VERSION ""

NS_ :

BS_:

BU_: SEAT HEADLAMP CLUSTER EMS ABS IMU KEYLESS_ECU ISG TESTER

BO_ 3221225472 VECTOR__INDEPENDENT_SIG_MSG: 0 Vector__XXX
 SG_ CC_TORQUE_REQ_STATUS_ENG_FB_Copy : 0|2@1+ (1,0) [0|2] " " Vector__XXX
 SG_ DNP_IMMOBILIZER_LAMP_INDICATION : 0|1@1+ (1,0) [0|1] "nan" Vector__XXX
 SG_ DNP_HEADLAMP_STATUS : 0|1@1+ (1,0) [0|1] "nan" Vector__XXX
 SG_ HEATED_GRIP_FEAT_EN : 0|1@1+ (1,0) [0|1] "nan" Vector__XXX
 SG_ HAPTIC_GRIP_FEAT_EN : 0|1@1+ (1,0) [0|1] "nan" Vector__XXX
 SG_ WINDSHIELD_FEAT_EN : 0|1@1+ (1,0) [0|1] "nan" Vector__XXX
 SG_ KEYLESS_FEAT_EN : 0|1@1+ (1,0) [0|1] "nan" Vector__XXX
 SG_ CLIMATIC_SEAT_FEAT_EN : 0|1@1+ (1,0) [0|1] "nan" Vector__XXX
 SG_ HOT_SEAT_FEAT_EN : 0|1@1+ (1,0) [0|1] "nan" Vector__XXX
 SG_ FEATURE_EN_LC : 0|1@1+ (1,0) [0|1] " " Vector__XXX

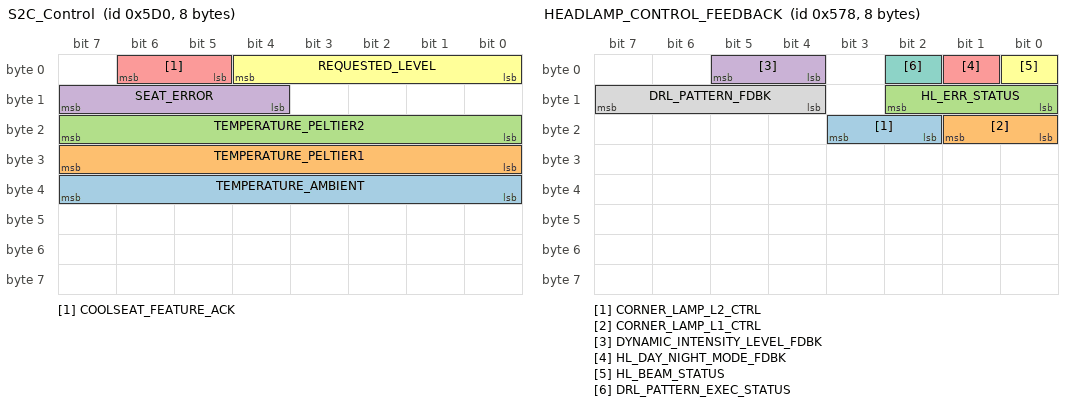
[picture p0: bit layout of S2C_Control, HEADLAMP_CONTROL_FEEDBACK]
BO_ 1488 S2C_Control: 8 SEAT
 SG_ TEMPERATURE_AMBIENT : 32|8@1+ (1,-20) [-20|235] "degC" Vector__XXX
 SG_ TEMPERATURE_PELTIER1 : 24|8@1+ (1,-20) [-20|235] "degC" Vector__XXX
 SG_ TEMPERATURE_PELTIER2 : 16|8@1+ (1,-20) [-20|235] "degC" Vector__XXX
 SG_ SEAT_ERROR : 12|4@1+ (1,0) [0|15] "nan" Vector__XXX
 SG_ COOLSEAT_FEATURE_ACK : 5|2@1+ (1,0) [0|3] "nan" Vector__XXX
 SG_ REQUESTED_LEVEL : 0|5@1+ (1,0) [0|31] " " Vector__XXX

BO_ 1489 C2S_Control: 8 Vector__XXX
 SG_ COOLSEAT_FEATURE_EN : 5|2@1+ (1,0) [0|3] "nan"  SEAT
 SG_ TARGET_LEVEL : 0|5@1+ (1,0) [0|31] " "  SEAT

BO_ 852 PecuOutputMsg2: 8 Vector__XXX
 SG_ KEYFOB_LOWBATTERY_WARN : 1|1@1+ (1,0) [0|1] "nan" Vector__XXX
 SG_ NO_KEYFOB_DETECTED_WARN : 0|1@1+ (1,0) [0|1] "nan" Vector__XXX

BO_ 1400 HEADLAMP_CONTROL_FEEDBACK: 8 Vector__XXX
 SG_ CORNER_LAMP_L2_CTRL : 18|2@1+ (1,0) [0|3] "nan"  CLUSTER
 SG_ CORNER_LAMP_L1_CTRL : 16|2@1+ (1,0) [0|3] "nan"  CLUSTER
 SG_ HL_ERR_STATUS : 8|3@1+ (1,0) [0|7] "nan"  CLUSTER
 SG_ DYNAMIC_INTENSITY_LEVEL_FDBK : 4|2@1+ (1,0) [0|3] "nan"  CLUSTER
 SG_ HL_DAY_NIGHT_MODE_FDBK : 1|1@1+ (1,0) [0|1] "nan"  CLUSTER
 SG_ HL_BEAM_STATUS : 0|1@1+ (1,0) [0|1] "nan"  CLUSTER
 SG_ DRL_PATTERN_EXEC_STATUS : 2|1@1+ (1,0) [0|1] "nan"  CLUSTER
 SG_ DRL_PATTERN_FDBK : 12|4@1+ (1,0) [0|15] "nan"  CLUSTER

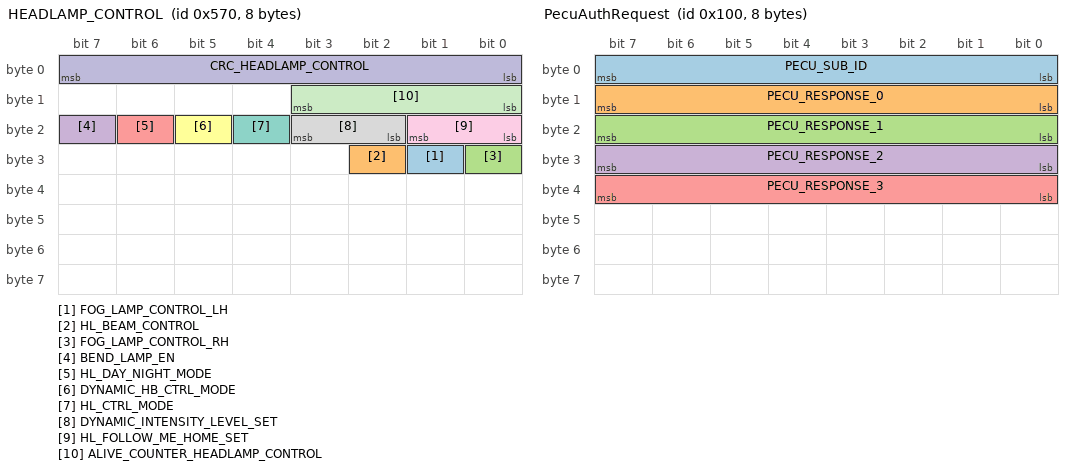
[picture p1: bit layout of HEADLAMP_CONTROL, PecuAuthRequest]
BO_ 1392 HEADLAMP_CONTROL: 8 CLUSTER
 SG_ FOG_LAMP_CONTROL_LH : 25|1@1+ (1,0) [0|1] "nan" Vector__XXX
 SG_ HL_BEAM_CONTROL : 26|1@1+ (1,0) [0|1] "nan"  HEADLAMP
 SG_ FOG_LAMP_CONTROL_RH : 24|1@1+ (1,0) [0|1] "nan" Vector__XXX
 SG_ BEND_LAMP_EN : 23|1@1+ (1,0) [0|1] "nan"  HEADLAMP
 SG_ HL_DAY_NIGHT_MODE : 22|1@1+ (1,0) [0|1] "nan"  HEADLAMP
 SG_ DYNAMIC_HB_CTRL_MODE : 21|1@1+ (1,0) [0|1] "nan"  HEADLAMP
 SG_ HL_CTRL_MODE : 20|1@1+ (1,0) [0|1] "nan"  HEADLAMP
 SG_ DYNAMIC_INTENSITY_LEVEL_SET : 18|2@1+ (1,0) [0|3] "nan"  HEADLAMP
 SG_ HL_FOLLOW_ME_HOME_SET : 16|2@1+ (1,0) [0|3] "nan"  HEADLAMP
 SG_ CRC_HEADLAMP_CONTROL : 0|8@1+ (1,0) [0|255] "nan"  HEADLAMP
 SG_ ALIVE_COUNTER_HEADLAMP_CONTROL : 8|4@1+ (1,0) [0|14] "nan"  HEADLAMP

BO_ 2017 TESTER_REQUEST_HECU_ABS: 8 TESTER
 SG_ TESTER_REQUEST_HECU_ABS : 0|64@1+ (1,0) [0|1] "nan" Vector__XXX

BO_ 2025 ABS_HECU_DIAG_RESPONSE: 8 ABS
 SG_ ABS_HECU_DIAG_RESPONSE : 0|64@1+ (1,0) [0|1] "nan"  TESTER

BO_ 2024 EMS_DIAG_RESPONSE: 8 EMS
 SG_ ABS_HECU_DIAG_RESPONSE : 0|64@1+ (1,0) [0|1] "nan" Vector__XXX

BO_ 256 PecuAuthRequest: 8 KEYLESS_ECU
 SG_ PECU_SUB_ID : 0|8@1+ (1,0) [0|255] "nan"  EMS
 SG_ PECU_RESPONSE_0 : 8|8@1+ (1,0) [0|255] "nan"  EMS
 SG_ PECU_RESPONSE_1 : 16|8@1+ (1,0) [0|255] "nan"  EMS
 SG_ PECU_RESPONSE_2 : 24|8@1+ (1,0) [0|255] "nan"  EMS
 SG_ PECU_RESPONSE_3 : 32|8@1+ (1,0) [0|255] "nan"  EMS

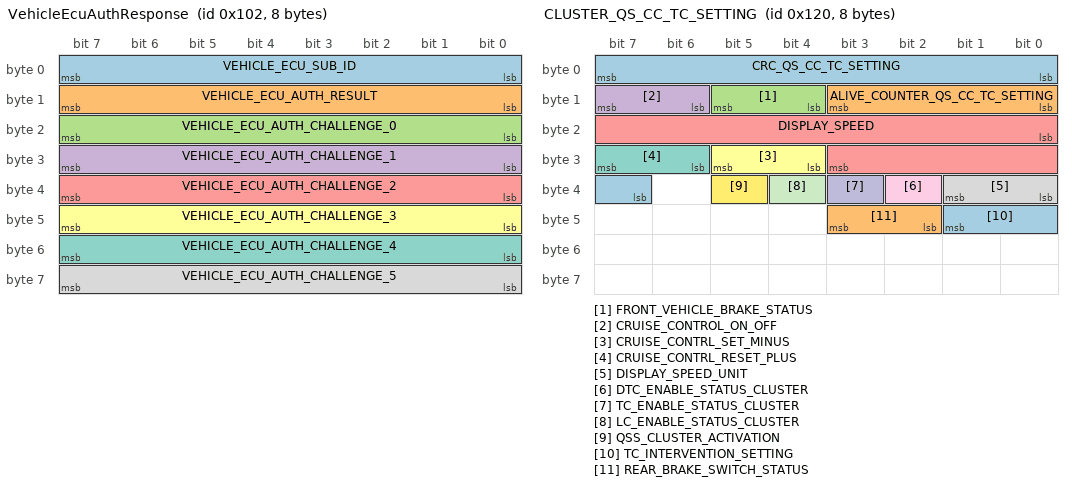
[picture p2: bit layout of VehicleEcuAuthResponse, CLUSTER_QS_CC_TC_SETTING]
BO_ 258 VehicleEcuAuthResponse: 8 EMS
 SG_ VEHICLE_ECU_SUB_ID : 0|8@1+ (1,0) [0|255] "nan"  KEYLESS_ECU
 SG_ VEHICLE_ECU_AUTH_RESULT : 8|8@1+ (1,0) [0|255] "nan"  KEYLESS_ECU
 SG_ VEHICLE_ECU_AUTH_CHALLENGE_0 : 16|8@1+ (1,0) [0|255] "nan"  KEYLESS_ECU
 SG_ VEHICLE_ECU_AUTH_CHALLENGE_1 : 24|8@1+ (1,0) [0|255] "nan"  KEYLESS_ECU
 SG_ VEHICLE_ECU_AUTH_CHALLENGE_2 : 32|8@1+ (1,0) [0|255] "nan"  KEYLESS_ECU
 SG_ VEHICLE_ECU_AUTH_CHALLENGE_3 : 40|8@1+ (1,0) [0|255] "nan"  KEYLESS_ECU
 SG_ VEHICLE_ECU_AUTH_CHALLENGE_4 : 48|8@1+ (1,0) [0|255] "nan"  KEYLESS_ECU
 SG_ VEHICLE_ECU_AUTH_CHALLENGE_5 : 56|8@1+ (1,0) [0|255] "nan"  KEYLESS_ECU

BO_ 288 CLUSTER_QS_CC_TC_SETTING: 8 CLUSTER
 SG_ CRC_QS_CC_TC_SETTING : 0|8@1+ (1,0) [0|255] "nan"  ABS,EMS
 SG_ ALIVE_COUNTER_QS_CC_TC_SETTING : 8|4@1+ (1,0) [0|14] "nan"  ABS,EMS
 SG_ FRONT_VEHICLE_BRAKE_STATUS : 12|2@1+ (1,0) [0|2] "nan"  ABS,EMS
 SG_ CRUISE_CONTROL_ON_OFF : 14|2@1+ (1,0) [0|2] "nan"  ABS,EMS
 SG_ DISPLAY_SPEED : 16|12@1+ (0.1,0) [0|409.4] "km/h"  ABS,EMS
 SG_ CRUISE_CONTRL_SET_MINUS : 28|2@1+ (1,0) [0|2] "nan"  ABS,EMS
 SG_ CRUISE_CONTRL_RESET_PLUS : 30|2@1+ (1,0) [0|2] "nan"  ABS,EMS
 SG_ DISPLAY_SPEED_UNIT : 32|2@1+ (1,0) [0|2] "nan"  ABS,EMS
 SG_ DTC_ENABLE_STATUS_CLUSTER : 34|1@1+ (1,0) [0|1] "nan"  ABS,EMS
 SG_ TC_ENABLE_STATUS_CLUSTER : 35|1@1+ (1,0) [0|1] "nan"  ABS,EMS
 SG_ LC_ENABLE_STATUS_CLUSTER : 36|1@1+ (1,0) [0|1] "nan"  ABS,EMS
 SG_ QSS_CLUSTER_ACTIVATION : 37|1@1+ (1,0) [0|1] "nan"  ABS,EMS
 SG_ TC_INTERVENTION_SETTING : 39|3@1+ (1,0) [0|6] "nan"  ABS,EMS
 SG_ REAR_BRAKE_SWITCH_STATUS : 42|2@1+ (1,0) [0|2] "nan"  ABS,EMS

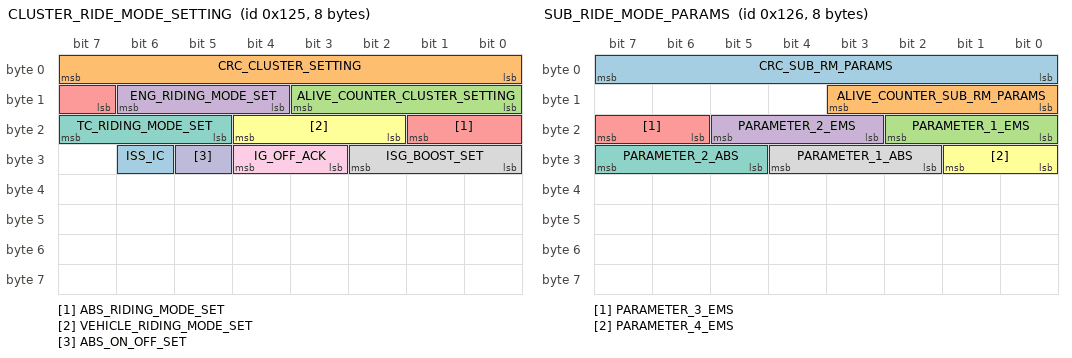
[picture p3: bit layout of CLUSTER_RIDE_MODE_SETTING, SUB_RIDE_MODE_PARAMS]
BO_ 293 CLUSTER_RIDE_MODE_SETTING: 8 CLUSTER
 SG_ ISS_IC : 30|1@1+ (1,0) [0|1] "nan"  EMS
 SG_ CRC_CLUSTER_SETTING : 0|8@1+ (1,0) [0|255] "nan"  EMS,ABS,ISG
 SG_ ALIVE_COUNTER_CLUSTER_SETTING : 8|4@1+ (1,0) [0|14] "nan"  EMS,ABS,ISG
 SG_ ENG_RIDING_MODE_SET : 12|3@1+ (1,0) [0|6] "nan"  EMS,ABS,ISG
 SG_ ABS_RIDING_MODE_SET : 15|3@1+ (1,0) [0|6] "nan"  EMS,ABS,ISG
 SG_ VEHICLE_RIDING_MODE_SET : 18|3@1+ (1,0) [0|6] "nan"  EMS,ABS,ISG
 SG_ TC_RIDING_MODE_SET : 21|3@1+ (1,0) [0|6] "nan"  EMS,ABS,ISG
 SG_ ISG_BOOST_SET : 24|3@1+ (1,0) [0|6] "nan"  EMS,ABS,ISG
 SG_ IG_OFF_ACK : 27|2@1+ (1,0) [0|2] "nan"  EMS,ABS,ISG
 SG_ ABS_ON_OFF_SET : 29|1@1+ (1,0) [0|1] "nan"  EMS,ABS,ISG

BO_ 294 SUB_RIDE_MODE_PARAMS: 8 CLUSTER
 SG_ CRC_SUB_RM_PARAMS : 0|8@1+ (1,0) [0|255] "nan"  EMS,ABS,ISG
 SG_ ALIVE_COUNTER_SUB_RM_PARAMS : 8|4@1+ (1,0) [0|14] "nan"  EMS,ABS,ISG
 SG_ PARAMETER_1_EMS : 16|3@1+ (1,0) [0|7] "nan"  EMS,ISG
 SG_ PARAMETER_2_EMS : 19|3@1+ (1,0) [0|7] "nan"  EMS,ISG
 SG_ PARAMETER_3_EMS : 22|2@1+ (1,0) [0|3] "nan"  EMS,ISG
 SG_ PARAMETER_4_EMS : 24|2@1+ (1,0) [0|3] "nan"  EMS,ISG
 SG_ PARAMETER_2_ABS : 29|3@1+ (1,0) [0|7] "nan"  ABS,ISG
 SG_ PARAMETER_1_ABS : 26|3@1+ (1,0) [0|7] "nan"  ABS,ISG

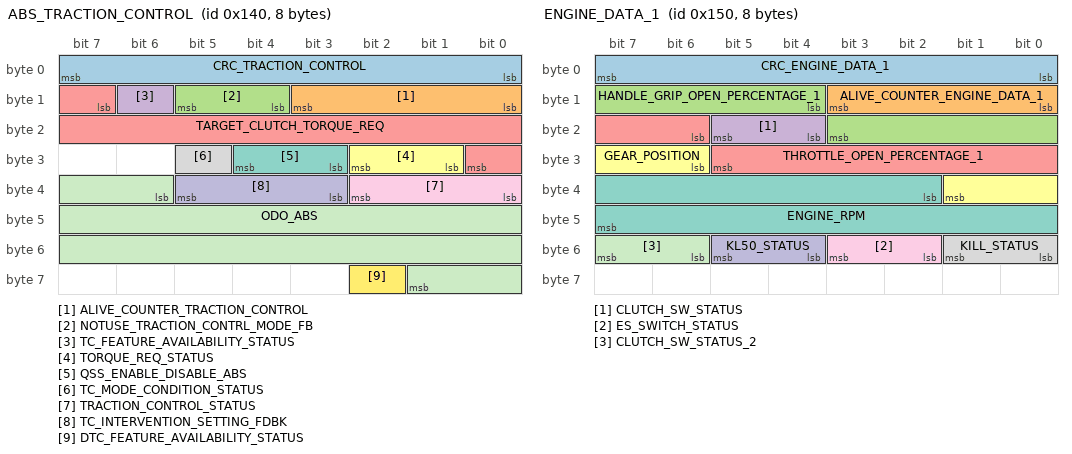
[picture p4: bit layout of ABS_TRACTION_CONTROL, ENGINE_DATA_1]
BO_ 320 ABS_TRACTION_CONTROL: 8 ABS
 SG_ CRC_TRACTION_CONTROL : 0|8@1+ (1,0) [0|255] "nan"  CLUSTER,EMS
 SG_ ALIVE_COUNTER_TRACTION_CONTROL : 8|4@1+ (1,0) [0|14] "nan"  CLUSTER,EMS
 SG_ NOTUSE_TRACTION_CONTRL_MODE_FB : 12|2@1+ (1,0) [0|2] "nan"  CLUSTER,EMS
 SG_ TC_FEATURE_AVAILABILITY_STATUS : 14|1@1+ (1,0) [0|1] "nan"  CLUSTER,EMS
 SG_ TARGET_CLUTCH_TORQUE_REQ : 15|10@1+ (0.1,-10) [-10|92.2] "Nm"  CLUSTER,EMS
 SG_ TORQUE_REQ_STATUS : 25|2@1+ (1,0) [0|2] "nan"  CLUSTER,EMS
 SG_ QSS_ENABLE_DISABLE_ABS : 27|2@1+ (1,0) [0|2] "nan"  CLUSTER,EMS
 SG_ TC_MODE_CONDITION_STATUS : 29|1@1+ (1,0) [0|1] "nan"  CLUSTER,EMS
 SG_ TRACTION_CONTROL_STATUS : 32|3@1+ (1,0) [0|6] "nan"  CLUSTER,EMS
 SG_ TC_INTERVENTION_SETTING_FDBK : 35|3@1+ (1,0) [0|6] "nan"  CLUSTER,EMS
 SG_ ODO_ABS : 38|20@1+ (1,0) [0|1048574] "km"  CLUSTER,EMS
 SG_ DTC_FEATURE_AVAILABILITY_STATUS : 58|1@1+ (1,0) [0|1] "nan"  CLUSTER,EMS

BO_ 336 ENGINE_DATA_1: 8 EMS
 SG_ CRC_ENGINE_DATA_1 : 0|8@1+ (1,0) [0|255] "nan"  ABS,CLUSTER,ISG
 SG_ ALIVE_COUNTER_ENGINE_DATA_1 : 8|4@1+ (1,0) [0|14] "nan"  ABS,CLUSTER,ISG
 SG_ HANDLE_GRIP_OPEN_PERCENTAGE_1 : 12|8@1+ (0.5,-20) [-20|107] "%"  ABS,CLUSTER,ISG
 SG_ CLUTCH_SW_STATUS : 20|2@1+ (1,0) [0|3] "nan"  ABS,CLUSTER,ISG
 SG_ THROTTLE_OPEN_PERCENTAGE_1 : 22|8@1+ (0.3937,0) [0|100] "%"  ABS,CLUSTER,ISG
 SG_ GEAR_POSITION : 30|4@1+ (1,0) [0|15] "nan"  ABS,CLUSTER,ISG
 SG_ ENGINE_RPM : 34|14@1+ (1,0) [0|16382] "1/min"  ABS,CLUSTER,ISG
 SG_ KILL_STATUS : 48|2@1+ (1,0) [0|2] "nan"  ABS,CLUSTER,ISG
 SG_ ES_SWITCH_STATUS : 50|2@1+ (1,0) [0|2] "nan"  ABS,CLUSTER,ISG
 SG_ KL50_STATUS : 52|2@1+ (1,0) [0|2] "nan"  ABS,CLUSTER,ISG
 SG_ CLUTCH_SW_STATUS_2 : 54|2@1+ (1,0) [0|3] "nan"  ABS,CLUSTER,ISG

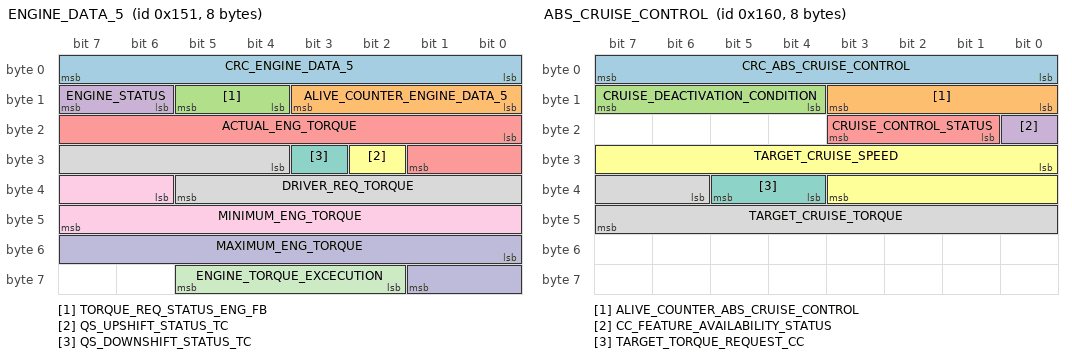
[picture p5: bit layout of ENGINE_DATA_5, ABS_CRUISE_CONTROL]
BO_ 337 ENGINE_DATA_5: 8 EMS
 SG_ CRC_ENGINE_DATA_5 : 0|8@1+ (1,0) [0|255] " "  ABS,CLUSTER
 SG_ ALIVE_COUNTER_ENGINE_DATA_5 : 8|4@1+ (1,0) [0|14] " "  ABS,CLUSTER
 SG_ TORQUE_REQ_STATUS_ENG_FB : 12|2@1+ (1,0) [0|2] " "  ABS,CLUSTER
 SG_ ENGINE_STATUS : 14|2@1+ (1,0) [0|2] " "  ABS,CLUSTER
 SG_ ACTUAL_ENG_TORQUE : 16|10@1+ (0.1,-10) [-10|92.2] "Nm"  ABS,CLUSTER
 SG_ QS_UPSHIFT_STATUS_TC : 26|1@1+ (1,0) [0|1] " "  ABS,CLUSTER
 SG_ QS_DOWNSHIFT_STATUS_TC : 27|1@1+ (1,0) [0|1] " "  ABS,CLUSTER
 SG_ DRIVER_REQ_TORQUE : 28|10@1+ (0.1,-10) [-10|92.2] "Nm"  ABS,CLUSTER
 SG_ MINIMUM_ENG_TORQUE : 38|10@1+ (0.1,-10) [-10|92.2] "Nm"  ABS,CLUSTER
 SG_ MAXIMUM_ENG_TORQUE : 48|10@1+ (0.1,-10) [-10|92.2] "Nm"  ABS,CLUSTER
 SG_ ENGINE_TORQUE_EXCECUTION : 58|4@1+ (1,0) [0|14] " "  ABS,CLUSTER

BO_ 352 ABS_CRUISE_CONTROL: 8 ABS
 SG_ CRC_ABS_CRUISE_CONTROL : 0|8@1+ (1,0) [0|255] "nan"  CLUSTER,EMS
 SG_ ALIVE_COUNTER_ABS_CRUISE_CONTROL : 8|4@1+ (1,0) [0|14] "nan"  CLUSTER,EMS
 SG_ CRUISE_DEACTIVATION_CONDITION : 12|4@1+ (1,0) [0|14] "nan"  CLUSTER,EMS
 SG_ CC_FEATURE_AVAILABILITY_STATUS : 16|1@1+ (1,0) [0|1] "nan"  CLUSTER,EMS
 SG_ CRUISE_CONTROL_STATUS : 17|3@1+ (1,0) [0|6] "nan"  CLUSTER,EMS
 SG_ TARGET_CRUISE_SPEED : 24|12@1+ (0.1,0) [0|409.4] "km/h"  CLUSTER,EMS
 SG_ TARGET_TORQUE_REQUEST_CC : 36|2@1+ (1,0) [0|2] "nan"  CLUSTER,EMS
 SG_ TARGET_CRUISE_TORQUE : 38|10@1+ (0.1,-10) [-10|92.2] "Nm"  CLUSTER,EMS

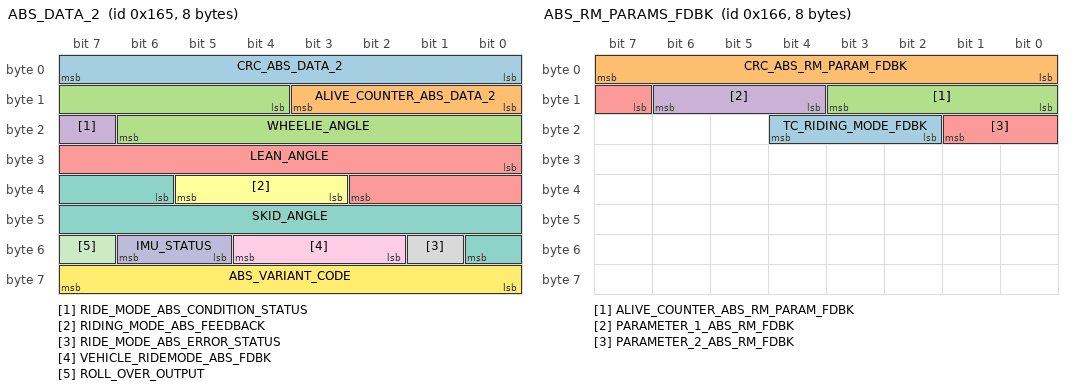
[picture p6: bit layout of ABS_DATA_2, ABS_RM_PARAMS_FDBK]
BO_ 357 ABS_DATA_2: 8 ABS
 SG_ CRC_ABS_DATA_2 : 0|8@1+ (1,0) [0|255] "nan"  EMS,CLUSTER
 SG_ ALIVE_COUNTER_ABS_DATA_2 : 8|4@1+ (1,0) [0|14] "nan"  EMS,CLUSTER
 SG_ WHEELIE_ANGLE : 12|11@1+ (0.1,-90) [-90|90] "deg"  EMS,CLUSTER
 SG_ RIDE_MODE_ABS_CONDITION_STATUS : 23|1@1+ (1,0) [0|1] "nan"  EMS,CLUSTER
 SG_ LEAN_ANGLE : 24|11@1+ (0.1,-90) [-90|90] "deg"  EMS,CLUSTER
 SG_ RIDING_MODE_ABS_FEEDBACK : 35|3@1+ (1,0) [0|6] "nan"  EMS,CLUSTER
 SG_ SKID_ANGLE : 38|11@1+ (0.1,-90) [-90|90] "deg"  EMS,CLUSTER
 SG_ RIDE_MODE_ABS_ERROR_STATUS : 49|1@1+ (1,0) [0|1] "nan"  EMS,CLUSTER
 SG_ VEHICLE_RIDEMODE_ABS_FDBK : 50|3@1+ (1,0) [0|6] "nan"  EMS,CLUSTER
 SG_ IMU_STATUS : 53|2@1+ (1,0) [0|3] "nan"  EMS,CLUSTER
 SG_ ROLL_OVER_OUTPUT : 55|1@1+ (1,0) [0|1] "nan"  EMS,CLUSTER
 SG_ ABS_VARIANT_CODE : 56|8@1+ (1,0) [0|254] "nan"  EMS,CLUSTER

BO_ 358 ABS_RM_PARAMS_FDBK: 8 ABS
 SG_ TC_RIDING_MODE_FDBK : 18|3@1+ (1,0) [0|6] "nan" Vector__XXX
 SG_ CRC_ABS_RM_PARAM_FDBK : 0|8@1+ (1,0) [0|255] "nan"  CLUSTER,EMS
 SG_ ALIVE_COUNTER_ABS_RM_PARAM_FDBK : 8|4@1+ (1,0) [0|14] "nan"  CLUSTER,EMS
 SG_ PARAMETER_1_ABS_RM_FDBK : 12|3@1+ (1,0) [0|7] "nan"  CLUSTER,EMS
 SG_ PARAMETER_2_ABS_RM_FDBK : 15|3@1+ (1,0) [0|7] "nan"  CLUSTER,EMS

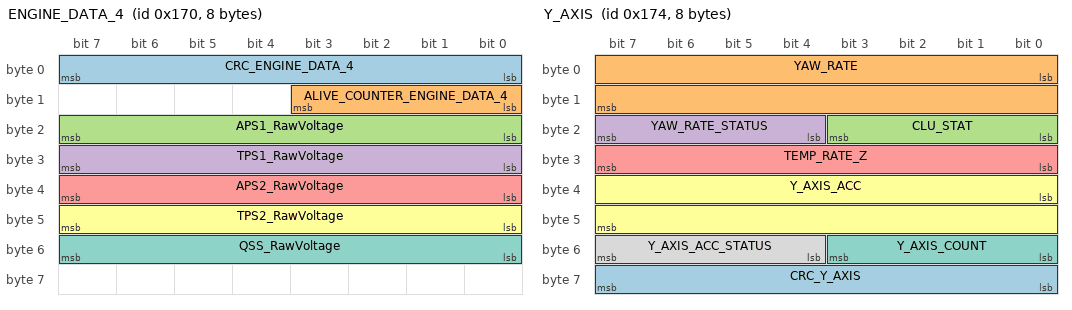
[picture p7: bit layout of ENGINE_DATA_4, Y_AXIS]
BO_ 368 ENGINE_DATA_4: 8 EMS
 SG_ CRC_ENGINE_DATA_4 : 0|8@1+ (1,0) [0|255] " "  ABS,CLUSTER
 SG_ ALIVE_COUNTER_ENGINE_DATA_4 : 8|4@1+ (1,0) [0|14] " "  ABS,CLUSTER
 SG_ APS1_RawVoltage : 16|8@1+ (0.0235,0) [0|5.9925] " "  ABS,CLUSTER
 SG_ TPS1_RawVoltage : 24|8@1+ (0.0235,0) [0|5.9925] " "  ABS,CLUSTER
 SG_ APS2_RawVoltage : 32|8@1+ (0.0235,0) [0|5.9925] " "  ABS,CLUSTER
 SG_ TPS2_RawVoltage : 40|8@1+ (0.0235,0) [0|5.9925] "nan"  ABS,CLUSTER
 SG_ QSS_RawVoltage : 48|8@1+ (0.0235,0) [0|5.9925] "nan"  ABS,CLUSTER

BO_ 372 Y_AXIS: 8 IMU
 SG_ CRC_Y_AXIS : 56|8@1+ (1,0) [0|255] " " Vector__XXX
 SG_ YAW_RATE : 0|16@1+ (0.005,-163.84) [-163.84|163.835] "°/s"  ABS
 SG_ CLU_STAT : 16|4@1+ (1,0) [0|15] "nan"  ABS
 SG_ YAW_RATE_STATUS : 20|4@1+ (1,0) [0|15] " "  ABS
 SG_ TEMP_RATE_Z : 24|8@1+ (1,-50) [-50|150] " "  ABS
 SG_ Y_AXIS_ACC : 32|16@1+ (0.00125,-40.957) [-40.957|40.958] "m/s^2"  ABS
 SG_ Y_AXIS_COUNT : 48|4@1+ (1,0) [0|15] " "  ABS
 SG_ Y_AXIS_ACC_STATUS : 52|4@1+ (1,0) [0|15] " "  ABS

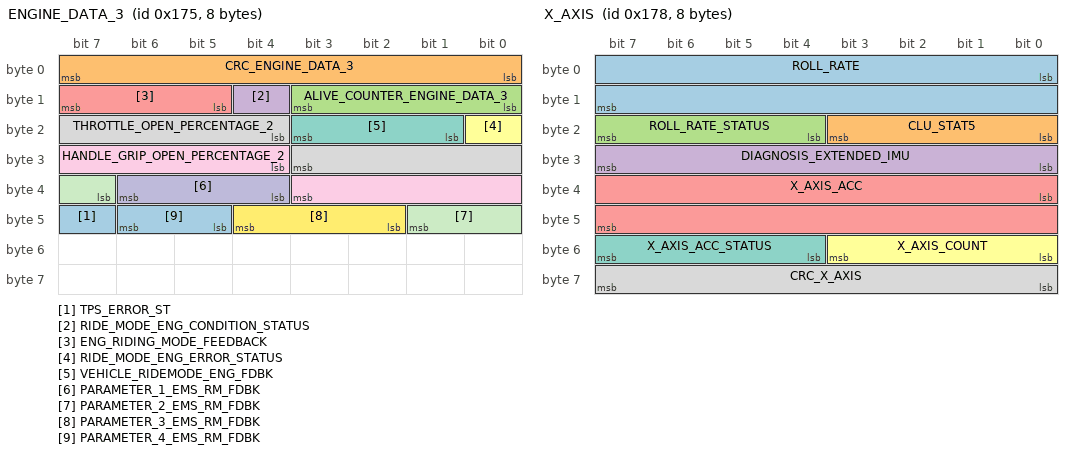
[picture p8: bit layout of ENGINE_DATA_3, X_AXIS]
BO_ 373 ENGINE_DATA_3: 8 EMS
 SG_ TPS_ERROR_ST : 47|1@1+ (1,0) [0|1] "nan" Vector__XXX
 SG_ CRC_ENGINE_DATA_3 : 0|8@1+ (1,0) [0|255] "nan"  ABS,CLUSTER
 SG_ ALIVE_COUNTER_ENGINE_DATA_3 : 8|4@1+ (1,0) [0|14] "nan"  ABS,CLUSTER
 SG_ RIDE_MODE_ENG_CONDITION_STATUS : 12|1@1+ (1,0) [0|1] "nan"  ABS,CLUSTER
 SG_ ENG_RIDING_MODE_FEEDBACK : 13|3@1+ (1,0) [0|6] "nan"  ABS,CLUSTER
 SG_ RIDE_MODE_ENG_ERROR_STATUS : 16|1@1+ (1,0) [0|1] "nan"  ABS,CLUSTER
 SG_ VEHICLE_RIDEMODE_ENG_FDBK : 17|3@1+ (1,0) [0|6] "nan"  ABS,CLUSTER
 SG_ THROTTLE_OPEN_PERCENTAGE_2 : 20|8@1+ (0.3937,0) [0|100] "%"  ABS,CLUSTER
 SG_ HANDLE_GRIP_OPEN_PERCENTAGE_2 : 28|8@1+ (0.5,-20) [-20|107] "%"  ABS,CLUSTER
 SG_ PARAMETER_1_EMS_RM_FDBK : 36|3@1+ (1,0) [0|3] "nan"  ABS,CLUSTER
 SG_ PARAMETER_2_EMS_RM_FDBK : 39|3@1+ (1,0) [0|3] "nan"  ABS,CLUSTER
 SG_ PARAMETER_3_EMS_RM_FDBK : 42|3@1+ (1,0) [0|3] "nan"  ABS,CLUSTER
 SG_ PARAMETER_4_EMS_RM_FDBK : 45|2@1+ (1,0) [0|3] "nan"  ABS,CLUSTER

BO_ 376 X_AXIS: 8 IMU
 SG_ ROLL_RATE : 0|16@1+ (0.005,-163.84) [-163.84|163.835] "°/s"  ABS
 SG_ CLU_STAT5 : 16|4@1+ (1,0) [0|15] "nan"  ABS
 SG_ ROLL_RATE_STATUS : 20|4@1+ (1,0) [0|15] " "  ABS
 SG_ DIAGNOSIS_EXTENDED_IMU : 24|8@1+ (1,-50) [-50|150] " "  ABS
 SG_ X_AXIS_ACC : 32|16@1+ (0.00125,-40.957) [-40.957|40.958] "m/s^2"  ABS
 SG_ X_AXIS_COUNT : 48|4@1+ (1,0) [0|15] " "  ABS
 SG_ X_AXIS_ACC_STATUS : 52|4@1+ (1,0) [0|15] " "  ABS
 SG_ CRC_X_AXIS : 56|8@1+ (1,0) [0|255] " "  ABS

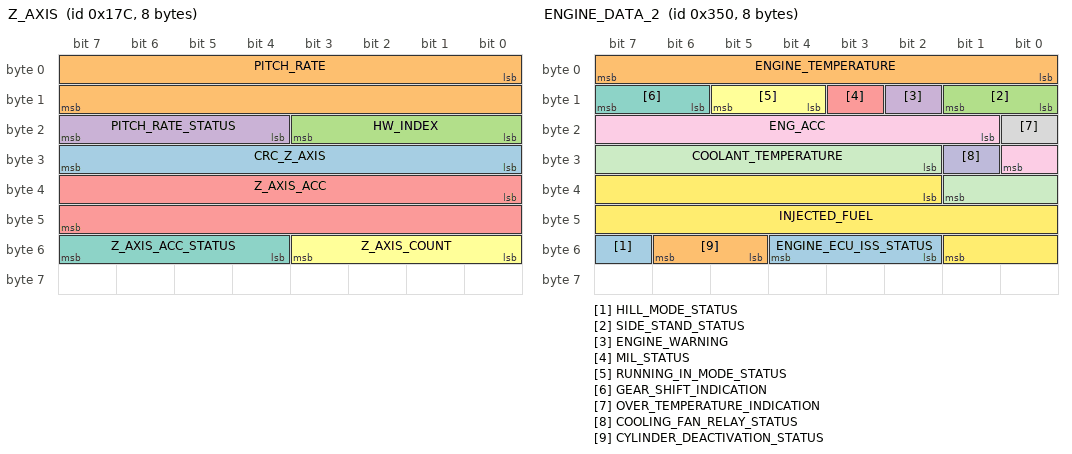
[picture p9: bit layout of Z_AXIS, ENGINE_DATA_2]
BO_ 380 Z_AXIS: 8 IMU
 SG_ CRC_Z_AXIS : 24|8@1+ (1,0) [0|255] " " Vector__XXX
 SG_ PITCH_RATE : 0|16@1+ (0.005,-163.84) [-163.84|163.835] "°/s"  ABS
 SG_ HW_INDEX : 16|4@1+ (1,0) [0|15] "nan"  ABS
 SG_ PITCH_RATE_STATUS : 20|4@1+ (1,0) [0|15] " "  ABS
 SG_ Z_AXIS_ACC : 32|16@1+ (0.00125,-40.957) [-40.957|40.958] "m/s^2"  ABS
 SG_ Z_AXIS_COUNT : 48|4@1+ (1,0) [0|15] " "  ABS
 SG_ Z_AXIS_ACC_STATUS : 52|4@1+ (1,0) [0|15] " "  ABS

BO_ 848 ENGINE_DATA_2: 8 EMS
 SG_ HILL_MODE_STATUS : 55|1@1+ (1,0) [0|1] "nan" Vector__XXX
 SG_ ENGINE_TEMPERATURE : 0|8@1+ (1,-25) [-25|200] "°C"  ABS,CLUSTER,ISG
 SG_ SIDE_STAND_STATUS : 8|2@1+ (1,0) [0|2] "nan"  ABS,CLUSTER,ISG
 SG_ ENGINE_WARNING : 10|1@1+ (1,0) [0|1] "nan"  ABS,CLUSTER,ISG
 SG_ MIL_STATUS : 11|1@1+ (1,0) [0|1] "nan"  ABS,CLUSTER,ISG
 SG_ RUNNING_IN_MODE_STATUS : 12|2@1+ (1,0) [0|2] "nan"  ABS,CLUSTER,ISG
 SG_ GEAR_SHIFT_INDICATION : 14|2@1+ (1,0) [0|2] "nan"  ABS,CLUSTER,ISG
 SG_ OVER_TEMPERATURE_INDICATION : 16|1@1+ (1,0) [0|1] "nan"  ABS,CLUSTER,ISG
 SG_ ENG_ACC : 17|8@1+ (0.05,-6) [-6|6] "g"  ABS,CLUSTER,ISG
 SG_ COOLING_FAN_RELAY_STATUS : 25|1@1+ (1,0) [0|1] "nan"  ABS,CLUSTER,ISG
 SG_ COOLANT_TEMPERATURE : 26|8@1+ (1,-25) [-25|200] "°C"  ABS,CLUSTER,ISG
 SG_ INJECTED_FUEL : 34|16@1+ (1,0) [0|65534] "µl"  ABS,CLUSTER,ISG
 SG_ ENGINE_ECU_ISS_STATUS : 50|3@1+ (1,0) [0|3] "nan"  ABS,CLUSTER,ISG
 SG_ CYLINDER_DEACTIVATION_STATUS : 53|2@1+ (1,0) [0|3] "nan"  ABS,CLUSTER,ISG

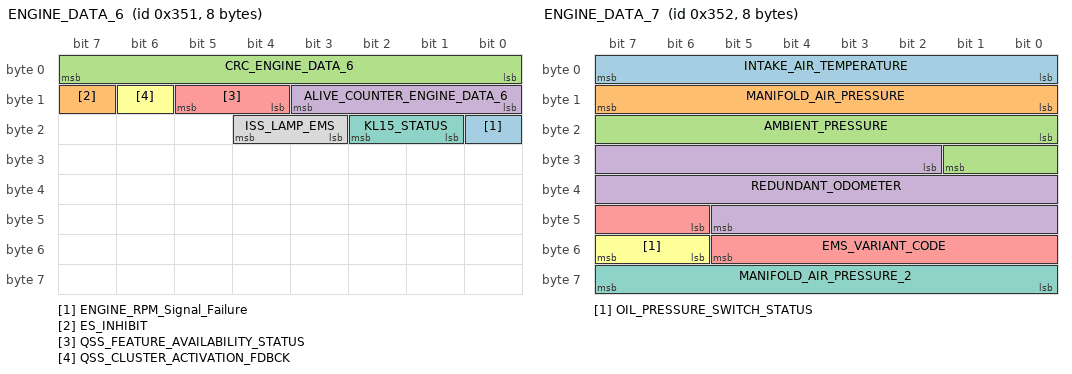
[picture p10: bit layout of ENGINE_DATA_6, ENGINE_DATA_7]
BO_ 849 ENGINE_DATA_6: 8 EMS
 SG_ ENGINE_RPM_Signal_Failure : 16|1@1+ (1,0) [0|1] "nan" Vector__XXX
 SG_ ES_INHIBIT : 15|1@1+ (1,0) [0|1] "nan" Vector__XXX
 SG_ CRC_ENGINE_DATA_6 : 0|8@1+ (1,0) [0|255] "nan"  ABS,CLUSTER,ISG
 SG_ ALIVE_COUNTER_ENGINE_DATA_6 : 8|4@1+ (1,0) [0|14] "nan"  ABS,CLUSTER,ISG
 SG_ QSS_FEATURE_AVAILABILITY_STATUS : 12|2@1+ (1,0) [0|2] "nan"  ABS,CLUSTER,ISG
 SG_ QSS_CLUSTER_ACTIVATION_FDBCK : 14|1@1+ (1,0) [0|1] "nan"  ABS,CLUSTER,ISG
 SG_ KL15_STATUS : 17|2@1+ (1,0) [0|2] "nan"  ABS,CLUSTER,ISG
 SG_ ISS_LAMP_EMS : 19|2@1+ (1,0) [0|2] "nan"  ABS,CLUSTER,ISG

BO_ 850 ENGINE_DATA_7: 8 EMS
 SG_ INTAKE_AIR_TEMPERATURE : 0|8@1+ (0.75,-48) [-48|142.5] "°C"  ABS,CLUSTER,ISG
 SG_ MANIFOLD_AIR_PRESSURE : 8|8@1+ (1,0) [0|254] "kPA"  ABS,CLUSTER,ISG
 SG_ AMBIENT_PRESSURE : 16|10@1+ (1,0) [0|1022] "hPA"  ABS,CLUSTER,ISG
 SG_ REDUNDANT_ODOMETER : 26|20@1+ (1,0) [0|1048574] "km"  ABS,CLUSTER,ISG
 SG_ EMS_VARIANT_CODE : 46|8@1+ (1,0) [0|254] "nan"  ABS,CLUSTER,ISG
 SG_ OIL_PRESSURE_SWITCH_STATUS : 54|2@1+ (1,0) [0|3] "nan"  ABS,CLUSTER,ISG
 SG_ MANIFOLD_AIR_PRESSURE_2 : 56|8@1+ (1,0) [0|254] "kPA"  ABS,CLUSTER,ISG

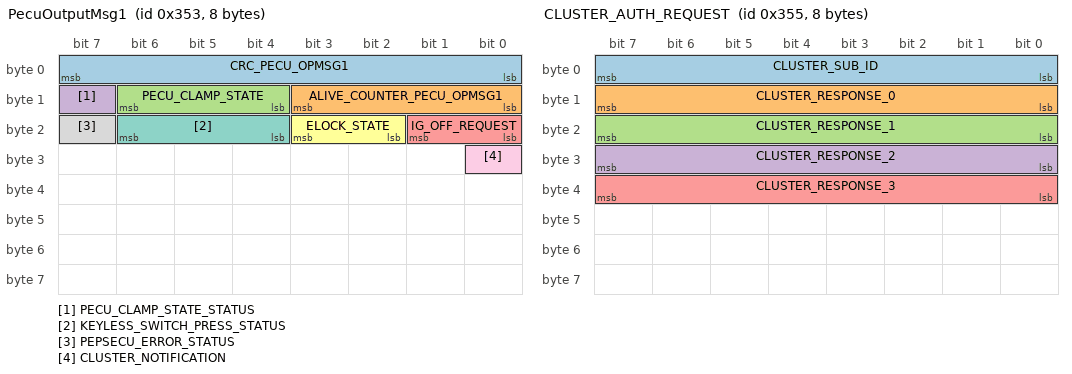
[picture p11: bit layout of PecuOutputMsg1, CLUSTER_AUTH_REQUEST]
BO_ 851 PecuOutputMsg1: 8 KEYLESS_ECU
 SG_ CRC_PECU_OPMSG1 : 0|8@1+ (1,0) [0|255] "nan"  CLUSTER,EMS
 SG_ ALIVE_COUNTER_PECU_OPMSG1 : 8|4@1+ (1,0) [0|14] "nan"  CLUSTER,EMS
 SG_ PECU_CLAMP_STATE : 12|3@1+ (1,0) [0|7] "nan"  CLUSTER,EMS
 SG_ PECU_CLAMP_STATE_STATUS : 15|1@1+ (1,0) [0|1] "nan"  CLUSTER,EMS
 SG_ IG_OFF_REQUEST : 16|2@1+ (1,0) [0|1] "nan"  CLUSTER,EMS
 SG_ ELOCK_STATE : 18|2@1+ (1,0) [0|3] "nan"  CLUSTER,EMS
 SG_ KEYLESS_SWITCH_PRESS_STATUS : 20|3@1+ (1,0) [0|7] "nan"  CLUSTER,EMS
 SG_ PEPSECU_ERROR_STATUS : 23|1@1+ (1,0) [0|1] "nan"  CLUSTER,EMS
 SG_ CLUSTER_NOTIFICATION : 24|1@1+ (1,0) [0|1] "nan"  CLUSTER,EMS

BO_ 853 CLUSTER_AUTH_REQUEST: 8 CLUSTER
 SG_ CLUSTER_SUB_ID : 0|8@1+ (1,0) [0|255] "nan"  KEYLESS_ECU
 SG_ CLUSTER_RESPONSE_0 : 8|8@1+ (1,0) [0|255] "nan"  KEYLESS_ECU
 SG_ CLUSTER_RESPONSE_1 : 16|8@1+ (1,0) [0|255] "nan"  KEYLESS_ECU
 SG_ CLUSTER_RESPONSE_2 : 24|8@1+ (1,0) [0|255] "nan"  KEYLESS_ECU
 SG_ CLUSTER_RESPONSE_3 : 32|8@1+ (1,0) [0|255] "nan"  KEYLESS_ECU

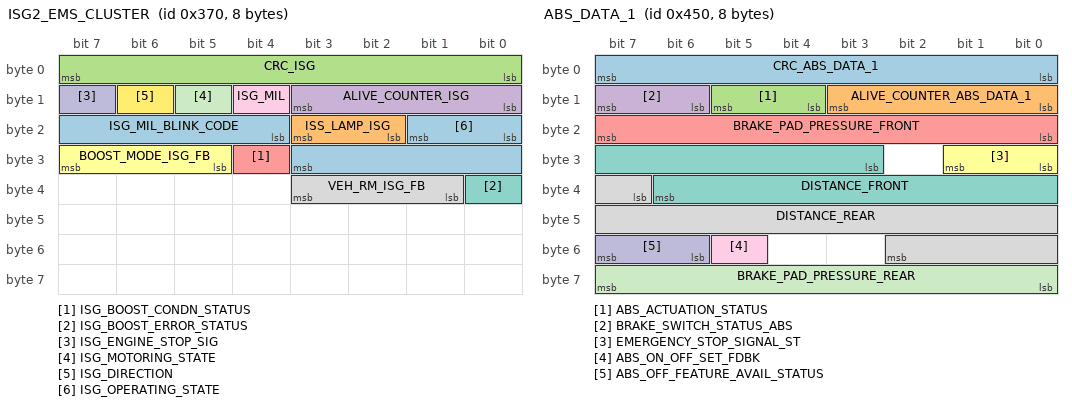
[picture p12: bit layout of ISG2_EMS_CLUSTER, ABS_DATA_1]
BO_ 880 ISG2_EMS_CLUSTER: 8 ISG
 SG_ ISG_MIL_BLINK_CODE : 20|8@1+ (1,0) [0|255] "nan" Vector__XXX
 SG_ ISS_LAMP_ISG : 18|2@1+ (1,0) [0|2] "nan" Vector__XXX
 SG_ CRC_ISG : 0|8@1+ (1,0) [0|255] "nan"  EMS,CLUSTER
 SG_ ALIVE_COUNTER_ISG : 8|4@1+ (1,0) [0|14] "nan"  EMS,CLUSTER
 SG_ ISG_BOOST_CONDN_STATUS : 28|1@1+ (1,0) [0|1] "nan"  EMS,CLUSTER
 SG_ BOOST_MODE_ISG_FB : 29|3@1+ (1,0) [0|6] "nan"  EMS,CLUSTER
 SG_ ISG_BOOST_ERROR_STATUS : 32|1@1+ (1,0) [0|1] "nan"  EMS,CLUSTER
 SG_ VEH_RM_ISG_FB : 33|3@1+ (1,0) [0|6] "nan"  EMS,CLUSTER
 SG_ ISG_MIL : 12|1@1+ (1,0) [0|1] "nan"  EMS,CLUSTER
 SG_ ISG_ENGINE_STOP_SIG : 15|1@1+ (1,0) [0|1] "nan"  EMS,CLUSTER
 SG_ ISG_MOTORING_STATE : 13|1@1+ (1,0) [0|1] "nan"  EMS,CLUSTER
 SG_ ISG_DIRECTION : 14|1@1+ (1,0) [0|1] "nan"  EMS,CLUSTER
 SG_ ISG_OPERATING_STATE : 16|2@1+ (1,0) [0|2] "nan"  EMS,CLUSTER

BO_ 1104 ABS_DATA_1: 8 ABS
 SG_ CRC_ABS_DATA_1 : 0|8@1+ (1,0) [0|255] "nan"  CLUSTER,EMS
 SG_ ALIVE_COUNTER_ABS_DATA_1 : 8|4@1+ (1,0) [0|14] "nan"  CLUSTER,EMS
 SG_ ABS_ACTUATION_STATUS : 12|2@1+ (1,0) [0|2] "nan"  CLUSTER,EMS
 SG_ BRAKE_SWITCH_STATUS_ABS : 14|2@1+ (1,0) [0|2] "nan"  CLUSTER,EMS
 SG_ BRAKE_PAD_PRESSURE_FRONT : 16|8@1+ (0.5,0) [0|127] "bar"  CLUSTER,EMS
 SG_ EMERGENCY_STOP_SIGNAL_ST : 24|2@1+ (1,0) [0|2] "nan"  CLUSTER,EMS
 SG_ DISTANCE_FRONT : 27|12@1+ (0.25,0) [0|999.75] "m"  CLUSTER,EMS
 SG_ DISTANCE_REAR : 39|12@1+ (0.25,0) [0|999.75] "m"  CLUSTER,EMS
 SG_ ABS_ON_OFF_SET_FDBK : 53|1@1+ (1,0) [0|1] "nan"  CLUSTER,EMS
 SG_ ABS_OFF_FEATURE_AVAIL_STATUS : 54|2@1+ (1,0) [0|3] "nan"  CLUSTER,EMS
 SG_ BRAKE_PAD_PRESSURE_REAR : 56|8@1+ (0.5,0) [0|127] "bar"  CLUSTER,EMS

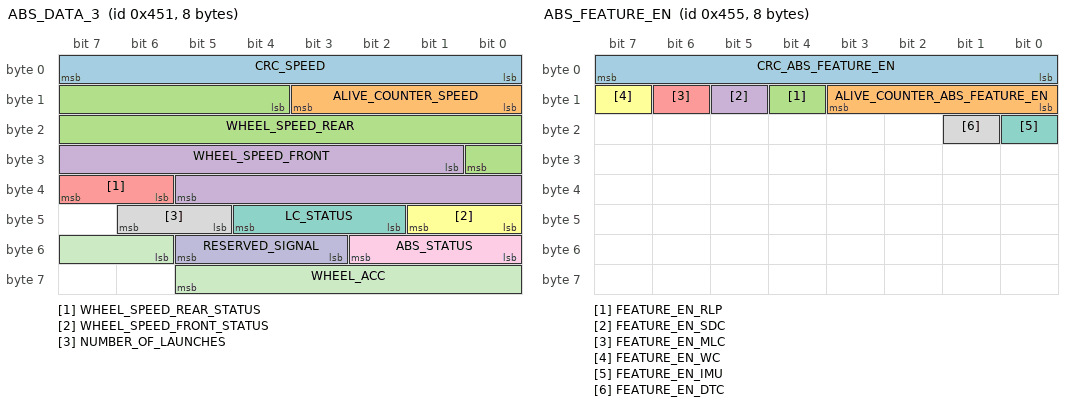
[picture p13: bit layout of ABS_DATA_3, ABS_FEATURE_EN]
BO_ 1105 ABS_DATA_3: 8 ABS
 SG_ CRC_SPEED : 0|8@1+ (1,0) [0|255] "nan"  EMS,CLUSTER
 SG_ ALIVE_COUNTER_SPEED : 8|4@1+ (1,0) [0|14] "nan"  EMS,CLUSTER
 SG_ WHEEL_SPEED_REAR : 12|13@1+ (0.05625,0) [0|460] "km/h"  EMS,CLUSTER
 SG_ WHEEL_SPEED_FRONT : 25|13@1+ (0.05625,0) [0|460] "km/h"  EMS,CLUSTER
 SG_ WHEEL_SPEED_REAR_STATUS : 38|2@1+ (1,0) [0|2] "nan"  EMS,CLUSTER
 SG_ WHEEL_SPEED_FRONT_STATUS : 40|2@1+ (1,0) [0|2] "nan"  EMS,CLUSTER
 SG_ LC_STATUS : 42|3@1+ (1,0) [0|6] "nan"  EMS,CLUSTER
 SG_ NUMBER_OF_LAUNCHES : 45|2@1+ (1,0) [0|3] "nan"  EMS,CLUSTER
 SG_ ABS_STATUS : 48|3@1+ (1,0) [0|6] "nan"  EMS,CLUSTER
 SG_ RESERVED_SIGNAL : 51|3@1+ (1,0) [0|7] "nan"  EMS,CLUSTER
 SG_ WHEEL_ACC : 54|8@1+ (0.05,-5) [-5|7.75] "g"  EMS,CLUSTER

BO_ 1109 ABS_FEATURE_EN: 8 ABS
 SG_ CRC_ABS_FEATURE_EN : 0|8@1+ (1,0) [0|255] "nan"  CLUSTER
 SG_ ALIVE_COUNTER_ABS_FEATURE_EN : 8|4@1+ (1,0) [0|14] " "  CLUSTER
 SG_ FEATURE_EN_RLP : 12|1@1+ (1,0) [0|1] " "  CLUSTER
 SG_ FEATURE_EN_SDC : 13|1@1+ (1,0) [0|1] " "  CLUSTER
 SG_ FEATURE_EN_MLC : 14|1@1+ (1,0) [0|1] " "  CLUSTER
 SG_ FEATURE_EN_WC : 15|1@1+ (1,0) [0|1] " "  CLUSTER
 SG_ FEATURE_EN_IMU : 16|1@1+ (1,0) [0|1] " "  CLUSTER
 SG_ FEATURE_EN_DTC : 17|1@1+ (1,0) [0|1] " "  CLUSTER

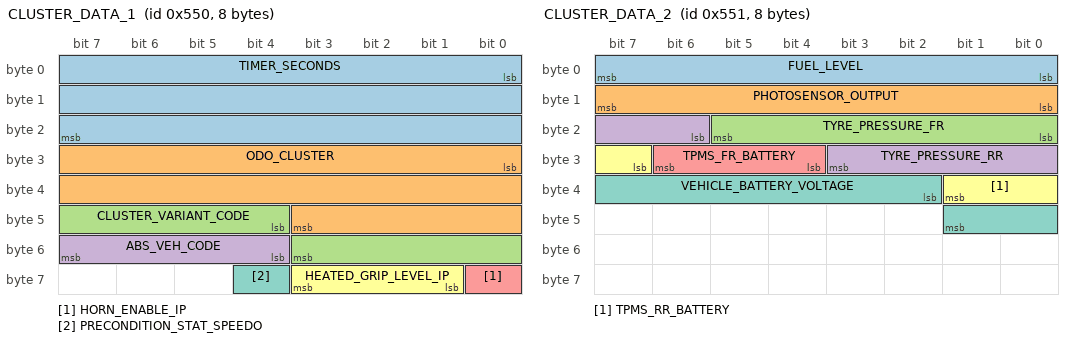
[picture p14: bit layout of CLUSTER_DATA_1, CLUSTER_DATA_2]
BO_ 1360 CLUSTER_DATA_1: 8 CLUSTER
 SG_ TIMER_SECONDS : 0|24@1+ (1,0) [0|16777215] "s"  ABS,EMS
 SG_ ODO_CLUSTER : 24|20@1+ (1,0) [0|1048574] "km"  ABS,EMS
 SG_ CLUSTER_VARIANT_CODE : 44|8@1+ (1,0) [0|254] "nan"  ABS,EMS
 SG_ ABS_VEH_CODE : 52|4@1+ (1,0) [0|14] "nan"  ABS,EMS
 SG_ HORN_ENABLE_IP : 56|1@1+ (1,0) [0|1] "nan"  ABS,EMS
 SG_ HEATED_GRIP_LEVEL_IP : 57|3@1+ (1,0) [0|3] "nan"  ABS,EMS
 SG_ PRECONDITION_STAT_SPEEDO : 60|1@1+ (1,0) [0|1] "nan"  ABS,EMS

BO_ 1361 CLUSTER_DATA_2: 8 CLUSTER
 SG_ FUEL_LEVEL : 0|8@1+ (0.1,0) [0|25.4] "l"  ABS,EMS,ISG
 SG_ PHOTOSENSOR_OUTPUT : 8|8@1+ (0.5,0) [0|100] "%"  ABS,EMS,ISG
 SG_ TYRE_PRESSURE_FR : 16|6@1+ (0.1,0) [0|6.2] "bar"  ABS,EMS,ISG
 SG_ TYRE_PRESSURE_RR : 22|6@1+ (0.1,0) [0|6.2] "bar"  ABS,EMS,ISG
 SG_ TPMS_FR_BATTERY : 28|3@1+ (20,0) [0|100] "%"  ABS,EMS,ISG
 SG_ TPMS_RR_BATTERY : 31|3@1+ (20,0) [0|100] "%"  ABS,EMS,ISG
 SG_ VEHICLE_BATTERY_VOLTAGE : 34|8@1+ (0.1,0) [0|25.4] "V"  ABS,EMS,ISG

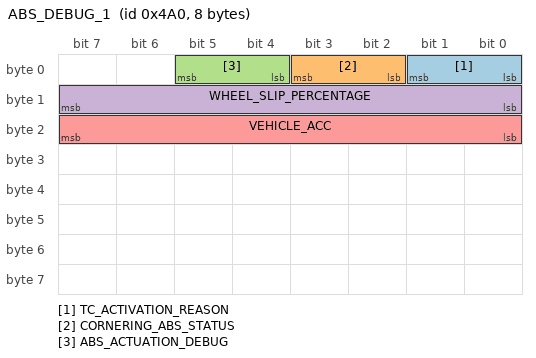
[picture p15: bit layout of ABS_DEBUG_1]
BO_ 1184 ABS_DEBUG_1: 8 ABS
 SG_ TC_ACTIVATION_REASON : 0|2@1+ (1,0) [0|3] "nan" Vector__XXX
 SG_ CORNERING_ABS_STATUS : 2|2@1+ (1,0) [0|3] "nan" Vector__XXX
 SG_ ABS_ACTUATION_DEBUG : 4|2@1+ (1,0) [0|3] "nan" Vector__XXX
 SG_ WHEEL_SLIP_PERCENTAGE : 8|8@1+ (0.5,0) [0|105] "%" Vector__XXX
 SG_ VEHICLE_ACC : 16|8@1+ (0.05,-6) [-6|6.75] "g" Vector__XXX

BO_ 2016 TESTER_REQUEST_EMS: 8 TESTER
 SG_ TESTER_REQUEST_EMS : 0|64@1+ (1,0) [0|1] "nan"  EMS,CLUSTER

CM_ "TVSM CAN matrix - ICE Intel
Version: 2.2
Revision date: 2024-07-29 00:00:00
Prepared by: SMM";
CM_ BO_ 3221225472 "This is a message for not used signals, created by Vector CANdb++ DBC OLE DB Provider.";
CM_ SG_ 3221225472 CC_TORQUE_REQ_STATUS_ENG_FB_Copy "This signal indicates the feedback from EMS to ABS for type of torque request";
CM_ SG_ 3221225472 HEATED_GRIP_FEAT_EN "This signal indicates the heated grip feature availability for the vehicle";
CM_ SG_ 3221225472 HAPTIC_GRIP_FEAT_EN "This signal indicates the haptic grip feature availability for the vehicle";
CM_ SG_ 3221225472 WINDSHIELD_FEAT_EN "This signal indicates the windshield adjustment feature availability for the vehicle";
CM_ SG_ 3221225472 KEYLESS_FEAT_EN "This signal indicates the keyless feature availability for the vehicle";
CM_ SG_ 3221225472 CLIMATIC_SEAT_FEAT_EN "This signal indicates the climatic seat availability for the vehicle";
CM_ SG_ 3221225472 HOT_SEAT_FEAT_EN "This signal indicates the hot seat availability for the vehicle";
CM_ SG_ 3221225472 FEATURE_EN_LC "Enable or disable Launch Control feature";
CM_ BO_ 1488 "The message will be reserved in case of Integrated Keyless unit with the cluster";
CM_ SG_ 1488 TEMPERATURE_AMBIENT "Ambient temperature measured at seat";
CM_ SG_ 1488 TEMPERATURE_PELTIER1 "Temperature measured on seat";
CM_ SG_ 1488 TEMPERATURE_PELTIER2 "Temperature measured on seat";
CM_ SG_ 1488 SEAT_ERROR "This signal provides the if there is any error triggered in seat";
CM_ SG_ 1488 COOLSEAT_FEATURE_ACK "Whether Coolseat feature is enabled in vehicle or not";
CM_ SG_ 1488 REQUESTED_LEVEL "This signal sends the feedback from seat for signal C2S_Control::TargetLevel.";
CM_ BO_ 1489 "The message will be reserved in case of Integrated Keyless unit with the cluster";
CM_ SG_ 1489 COOLSEAT_FEATURE_EN "Whether Coolseat feature is enabled in vehicle or not";
CM_ SG_ 1489 TARGET_LEVEL "This signal sends the feedback from seat for signal C2S_Control::TargetLevel.";
CM_ BO_ 852 "The message will be reserved in case of Integrated Keyless unit with the cluster";
CM_ SG_ 852 KEYFOB_LOWBATTERY_WARN "Keyfob Low battery indication warning";
CM_ SG_ 852 NO_KEYFOB_DETECTED_WARN "Keyfob not found in defined vicinity warning";
CM_ SG_ 1400 CORNER_LAMP_L2_CTRL "This signal is used to control  level 2 cornering lamps";
CM_ SG_ 1400 CORNER_LAMP_L1_CTRL "This signal is used to control  level 1 cornering lamps";
CM_ SG_ 1400 HL_ERR_STATUS "Indicates error present in HL ";
CM_ SG_ 1400 DYNAMIC_INTENSITY_LEVEL_FDBK "This signal indicates feedback for headlamp intensity control level. 
This is applicable for both Auto & manual mode.  
Headlamp controller shall controll the intensity of HB only based on this message.";
CM_ SG_ 1400 HL_DAY_NIGHT_MODE_FDBK "This signal indicates feedback for headlamp control request. 
The Headlamp control - Day / Night - shall be done by the headlamp comtroller based on this message";
CM_ SG_ 1400 HL_BEAM_STATUS "Indictaes if HB or LB is enabled in HL. 
To be used for high beam tell tale activation in speedometer
Provision for N325)";
CM_ SG_ 1400 DRL_PATTERN_EXEC_STATUS "This signal indicates whether the patern change input from the user is excecuted or not";
CM_ SG_ 1400 DRL_PATTERN_FDBK "Feedback for DRL_PATTERN_SET
The last updated input from the Speedometer shall be stored in the Headlamp controller before Ignition key off.";
CM_ SG_ 1392 FOG_LAMP_CONTROL_LH "This signal is to control LH Fog lamp";
CM_ SG_ 1392 HL_BEAM_CONTROL "This signal indicates the switch Input to Headlamp for Beam Control";
CM_ SG_ 1392 FOG_LAMP_CONTROL_RH "This signal is to control RH Fog lamp";
CM_ SG_ 1392 BEND_LAMP_EN "This signal indicates the switch Input to Headlamp for Beam Control";
CM_ SG_ 1392 HL_DAY_NIGHT_MODE "This signal indicates headlamp control request. 
The Headlamp control - Day / Night - shall be done by the headlamp comtroller based on this message";
CM_ SG_ 1392 DYNAMIC_HB_CTRL_MODE "This signal indicates the level (i.e time) for which the lamps to be turned ON after ignition OFF. 
The last updated input from the Speedometer shall be stored in the Headlamp controller before Ignition key off.";
CM_ SG_ 1392 HL_CTRL_MODE "This signal indicates the level (i.e time) for which the lamps to be turned ON after ignition OFF. 
The last updated input from the Speedometer shall be stored in the Headlamp controller before Ignition key off.";
CM_ SG_ 1392 DYNAMIC_INTENSITY_LEVEL_SET "This signal indicates headlamp intensity control level. 
This is applicable for both Auto & manual mode.  
Headlamp controller shall controll the intensity of HB only based on this message.";
CM_ SG_ 1392 HL_FOLLOW_ME_HOME_SET "This signal indicates the level (i.e time) for which the lamps to be turned ON after ignition OFF. 
The last updated input from the Speedometer shall be stored in the Headlamp controller before Ignition key off.";
CM_ SG_ 1392 CRC_HEADLAMP_CONTROL "Standard application CRC to hedge. 
This signal uses the application CRC-ID = 92 (0x5C)";
CM_ SG_ 1392 ALIVE_COUNTER_HEADLAMP_CONTROL "Standard protection!";
CM_ BO_ 2017 "The message is for tester communication (debug message)";
CM_ SG_ 2017 TESTER_REQUEST_HECU_ABS "The signal is used as communication between tester tool and cluster unit.";
CM_ BO_ 2025 "The message is for tester communication (debug message)";
CM_ SG_ 2025 ABS_HECU_DIAG_RESPONSE "The signal is used as communication between tester tool and cluster unit.";
CM_ BO_ 2024 "The message is for tester communication (debug message)";
CM_ SG_ 2024 ABS_HECU_DIAG_RESPONSE "The signal is used as communication between tester tool and cluster unit.";
CM_ BO_ 256 "The message Tx will change based on the type of keyless module (integrated or separate; LF/RF or BT or RFID).
1) Separate RF unit- Tx: KEYLESS_ECU
2) Integrated BT unit- Tx: VCU";
CM_ SG_ 256 PECU_SUB_ID "Subject ID i.e. Authentication Request or Reply message";
CM_ SG_ 256 PECU_RESPONSE_0 "Authentication Response Byte 0";
CM_ SG_ 256 PECU_RESPONSE_1 "Authentication Response Byte 1";
CM_ SG_ 256 PECU_RESPONSE_2 "Authentication Response Byte 2";
CM_ SG_ 256 PECU_RESPONSE_3 "Authentication Response Byte 3";
CM_ BO_ 258 "The message Rx will change based on the type of keyless module (integrated or separate; LF/RF or BT or RFID).
1) Separate RF unit- Rx: KEYLESS_ECU
2) Integrated BT unit- Rx: VCU";
CM_ SG_ 258 VEHICLE_ECU_SUB_ID "Subject ID i.e. Random number or Authentication result";
CM_ SG_ 258 VEHICLE_ECU_AUTH_RESULT "Authentication Result";
CM_ SG_ 258 VEHICLE_ECU_AUTH_CHALLENGE_0 "Authentication Challenge Byte 0";
CM_ SG_ 258 VEHICLE_ECU_AUTH_CHALLENGE_1 "Authentication Challenge Byte 1";
CM_ SG_ 258 VEHICLE_ECU_AUTH_CHALLENGE_2 "Authentication Challenge Byte 2";
CM_ SG_ 258 VEHICLE_ECU_AUTH_CHALLENGE_3 "Authentication Challenge Byte 3";
CM_ SG_ 258 VEHICLE_ECU_AUTH_CHALLENGE_4 "Authentication Challenge Byte 4";
CM_ SG_ 258 VEHICLE_ECU_AUTH_CHALLENGE_5 "Authentication Challenge Byte 5";
CM_ BO_ 288 "The message is for Cruise control, Traction control, Quick shift, Drag torque control, Launch control features setting from User";
CM_ SG_ 288 CRC_QS_CC_TC_SETTING "Standard application CRC to hedge.
This signal uses the application CRC-ID = 75(Dec)  = 0x48";
CM_ SG_ 288 ALIVE_COUNTER_QS_CC_TC_SETTING "Standard Protection";
CM_ SG_ 288 FRONT_VEHICLE_BRAKE_STATUS "It indicates the actuation of  front brake switch if seaparately connected to speedometer, 
else it indicates the vehicle brake actuation if both switches are connected parallely.";
CM_ SG_ 288 CRUISE_CONTROL_ON_OFF "This signal shows status of Cruise ON/OFF button";
CM_ SG_ 288 DISPLAY_SPEED "This signal contains the speed of the front wheel in km / h.  Value transferred is with error added to true speed received from ABS. In case of primary sensor failure, secondary sensor data is displayed.
";
CM_ SG_ 288 CRUISE_CONTRL_SET_MINUS "This signal shows status of Cruise SET/-  button";
CM_ SG_ 288 CRUISE_CONTRL_RESET_PLUS "This signal shows status of Cruise RESET/+  button";
CM_ SG_ 288 DTC_ENABLE_STATUS_CLUSTER "This signal indicates Drag torque control enable/disable status by rider";
CM_ SG_ 288 TC_ENABLE_STATUS_CLUSTER "This signal indicates Traction control enable/disable status by rider";
CM_ SG_ 288 LC_ENABLE_STATUS_CLUSTER "This signal indicates Launch control enable/disable status by rider";
CM_ SG_ 288 QSS_CLUSTER_ACTIVATION "This signal allows to enable or disable quickshifter functionality via cluster";
CM_ SG_ 288 TC_INTERVENTION_SETTING "Reserved in N600";
CM_ SG_ 288 REAR_BRAKE_SWITCH_STATUS "It indicates the actuation of  rear brake switch if separately connected to speedometer";
CM_ BO_ 293 "The message is for the Ride mode message request from the cluster.";
CM_ SG_ 293 ISS_IC "This is used to indicate if the ISS feature is enabled/disabled from Cluster to ISG/EMS
Request made by rider to turn or turn off ISS feature on vehicle";
CM_ SG_ 293 CRC_CLUSTER_SETTING "Standard application CRC to hedge.
This signal uses the application CRC-ID = 80 (Dec) = 0x50";
CM_ SG_ 293 ALIVE_COUNTER_CLUSTER_SETTING "Standard protection!";
CM_ SG_ 293 ENG_RIDING_MODE_SET "The signal will be reused as Engine riding mode request  in case of Custom ride mode available for the project
";
CM_ SG_ 293 TC_RIDING_MODE_SET "This signal indicates mode setting related to traction control";
CM_ SG_ 293 IG_OFF_ACK "This signal indicates response of IG OFF request from Keyless ECU. 
In case of integrated Keyless Unit, the signal indicates Igniton Out status from the cluster.";
CM_ SG_ 293 ABS_ON_OFF_SET "Request made by cluster to enable/disable ABS switch off functionality. 
Requires signal ABS_OFF_AVAILABILITY_STATUS to understand if rear ABS/complete ABS can be enabled/disabled";
CM_ BO_ 294 "Message for setting sub ride mode parameters. To be sent only when vehicle is in Custom ride mode.";
CM_ SG_ 294 CRC_SUB_RM_PARAMS "Standard application CRC to hedge.
This signal uses the application CRC-ID = 81 (Dec) = 0x51";
CM_ SG_ 294 ALIVE_COUNTER_SUB_RM_PARAMS "Standard protection!";
CM_ SG_ 294 PARAMETER_1_EMS "This signal indicates selection of Acceleration for custom ride mode";
CM_ SG_ 294 PARAMETER_2_EMS "This signal indicates selection of Deceleration for custom ride mode";
CM_ SG_ 294 PARAMETER_3_EMS "This signal indicates selection of Quickshift Assist for custom ride mode";
CM_ SG_ 294 PARAMETER_4_EMS "This signal indicates selection of Idle RPM for custom ride mode";
CM_ SG_ 294 PARAMETER_2_ABS "This signal indicates selection of Braking for custom ride mode";
CM_ SG_ 294 PARAMETER_1_ABS "This signal indicates the Wheelie control response from the ABS in custom ride mode";
CM_ BO_ 320 "The message indicates the Traction control, Drag torque control feature details from ABS unit";
CM_ SG_ 320 CRC_TRACTION_CONTROL "Standard application CRC to hedge.
This signal uses the application CRC-ID = 25 (Dec) = 0x19";
CM_ SG_ 320 ALIVE_COUNTER_TRACTION_CONTROL "Standard protection!";
CM_ SG_ 320 NOTUSE_TRACTION_CONTRL_MODE_FB "Not in use for N600, N325";
CM_ SG_ 320 TC_FEATURE_AVAILABILITY_STATUS "This signal displays the availability of Traction Control in ABS";
CM_ SG_ 320 TARGET_CLUTCH_TORQUE_REQ "This signal indicates DTC torque request value";
CM_ SG_ 320 TORQUE_REQ_STATUS "This signal indicates the TC torque request to EMS";
CM_ SG_ 320 QSS_ENABLE_DISABLE_ABS "This signal indicates enable or disable quickshifter functionality by ABS for TC";
CM_ SG_ 320 TC_MODE_CONDITION_STATUS "This signal idnicated if the condition for changing ABS TC  mode is met or not met";
CM_ SG_ 320 TRACTION_CONTROL_STATUS "This signal displays the TC status";
CM_ SG_ 320 ODO_ABS "This signal contains the total distance covered by the motorcycle.";
CM_ SG_ 320 DTC_FEATURE_AVAILABILITY_STATUS "This signal displays the availability of Drag Torque Control in ABS";
CM_ SG_ 336 CRC_ENGINE_DATA_1 "Standard application CRC to hedge.
This signal uses the application CRC-ID = 50 (Dec) = 0x32";
CM_ SG_ 336 ALIVE_COUNTER_ENGINE_DATA_1 "Standard protection!";
CM_ SG_ 336 HANDLE_GRIP_OPEN_PERCENTAGE_1 "This signal shall transmit the driver's request (faw_rel_w) in percent. This provides the driver's dependent is the driving value transmitter (throttle grip), the influence of the different throttle grip maps (mode) is here given.";
CM_ SG_ 336 THROTTLE_OPEN_PERCENTAGE_1 "This signal contains throttle position in terms of %";
CM_ SG_ 336 GEAR_POSITION "This signal indicates which gear has been lodged.";
CM_ SG_ 336 ENGINE_RPM "This signal indicates the engine speed.";
CM_ SG_ 336 KILL_STATUS "By this signal the driver to the Actuation of the emergency-stop switch display. When actuated emergency stop switch, the motor controller switches the fuel pump, ignition and injection immediately. The starter relay is no longer activated";
CM_ SG_ 336 ES_SWITCH_STATUS "By this signal the driver to the Actuation of the emergency-stop switch display. When actuated emergency stop switch, the motor controller switches the fuel pump, ignition and injection immediately. The starter relay is no longer activated";
CM_ SG_ 336 KL50_STATUS "This signal indicates whether the starter relay is energized.
It is already set at the actuation of the start button and is therefore before the meshing of the starter at your disposal
For ISG Set indicates motoring can happen and 0 no motoring";
CM_ SG_ 337 CRC_ENGINE_DATA_5 "Standard application CRC to hedge.
This signal uses the application CRC-ID = 45(Dec)  = 0x2D";
CM_ SG_ 337 ALIVE_COUNTER_ENGINE_DATA_5 "Standard Protection";
CM_ SG_ 337 TORQUE_REQ_STATUS_ENG_FB "This signal indicates the feedback from EMS to ABS for type of torque request";
CM_ SG_ 337 ENGINE_STATUS "This signal indicates the Engine status";
CM_ SG_ 337 ACTUAL_ENG_TORQUE "This signal indicates the actual engine torque";
CM_ SG_ 337 QS_UPSHIFT_STATUS_TC "This signal indicates QS execution status";
CM_ SG_ 337 QS_DOWNSHIFT_STATUS_TC "This signal indicates QS downshift status";
CM_ SG_ 337 DRIVER_REQ_TORQUE "This signal indicates the Driver requested torque from EMS to ABS";
CM_ SG_ 337 MINIMUM_ENG_TORQUE "For the given gear min engine torque that engine can operate";
CM_ SG_ 337 MAXIMUM_ENG_TORQUE "For the given gear max engine torque that engine can operate";
CM_ SG_ 337 ENGINE_TORQUE_EXCECUTION "Present active torque input as considered by EMS";
CM_ SG_ 352 CRC_ABS_CRUISE_CONTROL "Standard application CRC to hedge.
This signal uses the application CRC-ID = 30(Dec)  = 0x1E";
CM_ SG_ 352 ALIVE_COUNTER_ABS_CRUISE_CONTROL "Standard Protection";
CM_ SG_ 352 CRUISE_DEACTIVATION_CONDITION "This signal displays the CC last deactivation condition in the same ignition cycle";
CM_ SG_ 352 CC_FEATURE_AVAILABILITY_STATUS "This signal allows to enable or disable CC functionality via cluster";
CM_ SG_ 352 CRUISE_CONTROL_STATUS "This signal displays the CC status ";
CM_ SG_ 352 TARGET_CRUISE_SPEED "This signal sends the cruise speed set by the ABS ECU";
CM_ SG_ 352 TARGET_TORQUE_REQUEST_CC "This signal indicates the feedback from EMS to ABS for type of torque request.
 Value>= 0x2 is considered as Invalid";
CM_ SG_ 352 TARGET_CRUISE_TORQUE "This signal indicates the delta torque required by HECU to maintain cruise speed";
CM_ SG_ 357 CRC_ABS_DATA_2 "Standard application CRC to hedge.
This signal uses the application CRC-ID = 90 (Dec) = 0x5A";
CM_ SG_ 357 ALIVE_COUNTER_ABS_DATA_2 "Standard protection!";
CM_ SG_ 357 RIDE_MODE_ABS_CONDITION_STATUS "This signal indicated if the condition for changing ABS ride mode is met or not met";
CM_ SG_ 357 RIDE_MODE_ABS_ERROR_STATUS "This signal indicates if there is any ride mode chnage related error in the system";
CM_ SG_ 357 VEHICLE_RIDEMODE_ABS_FDBK "This signal gives the currently active vehicle ride mode of the ABS system.";
CM_ SG_ 357 IMU_STATUS "This signal gives the operational status of the IMU ";
CM_ SG_ 357 ROLL_OVER_OUTPUT "This signal indicates the vehicle roll-over happened  and engine cut-off request based on lean angle data";
CM_ SG_ 357 ABS_VARIANT_CODE "This signal gives the currently active features enabled in the system";
CM_ SG_ 358 TC_RIDING_MODE_FDBK "This signal indicates mode setting related to traction control
Valid for N325";
CM_ SG_ 358 CRC_ABS_RM_PARAM_FDBK "Standard application CRC to hedge.
This signal uses the application CRC-ID = 85 (Dec) = 0x55";
CM_ SG_ 358 ALIVE_COUNTER_ABS_RM_PARAM_FDBK "Standard protection!";
CM_ SG_ 358 PARAMETER_1_ABS_RM_FDBK "This signal indicates selection of Braking for custom ride mode";
CM_ SG_ 358 PARAMETER_2_ABS_RM_FDBK "This signal indicates the Wheelie control response from the ABS in custom ride mode";
CM_ SG_ 368 CRC_ENGINE_DATA_4 "Standard application CRC to hedge.
This signal uses the application CRC-ID = 100 (Dec)  = 0x64";
CM_ SG_ 368 ALIVE_COUNTER_ENGINE_DATA_4 "Standard Protection";
CM_ SG_ 368 APS1_RawVoltage "This signal indicates the raw voltage of APS 1 sensor";
CM_ SG_ 368 TPS1_RawVoltage "This signal indicates the raw voltage of TPS 1 sensor";
CM_ SG_ 368 APS2_RawVoltage "This signal indicates the raw voltage of APS 2 sensor";
CM_ SG_ 368 TPS2_RawVoltage "This signal indicates the raw voltage of TPS 2 sensor";
CM_ SG_ 368 QSS_RawVoltage "This signal indicates the raw voltage of QSS sensor";
CM_ SG_ 373 TPS_ERROR_ST "Request made by cluster to enable/disable ABS switch off functionality. 
Requires signal ABS_OFF_AVAILABILITY_STATUS to understand if rear ABS/complete ABS can be enabled/disabled";
CM_ SG_ 373 CRC_ENGINE_DATA_3 "Standard application CRC to hedge.
This signal uses the application CRC-ID = 40 (Dec) = 0x28";
CM_ SG_ 373 ALIVE_COUNTER_ENGINE_DATA_3 "Standard protection!";
CM_ SG_ 373 RIDE_MODE_ENG_CONDITION_STATUS "This signal indicates if the conditions for ride mode change are met or not met";
CM_ SG_ 373 ENG_RIDING_MODE_FEEDBACK "This signal indicates the engine Ride mode feedback from Engine ECU for cluster request. 
In case of Custom ride mode, the signal is reused as engine pedal map response from the Engine ECU.";
CM_ SG_ 373 RIDE_MODE_ENG_ERROR_STATUS "This signal indicates if there is any ride mode change related error in the system";
CM_ SG_ 373 THROTTLE_OPEN_PERCENTAGE_2 "This signal contains throttle position in terms of %";
CM_ SG_ 373 HANDLE_GRIP_OPEN_PERCENTAGE_2 "This signal shall transmit the driver's request (faw_rel_w) in percent. This provides the driver's dependent is the driving value transmitter (throttle grip), the influence of the different throttle grip maps (mode) is here given.";
CM_ SG_ 373 PARAMETER_1_EMS_RM_FDBK "This signal indicates the Acceleration response from the Engine ECU in custom ride mode";
CM_ SG_ 373 PARAMETER_2_EMS_RM_FDBK "This signal indicates the Deceleration level response from the Engine ECU in custom ride mode";
CM_ SG_ 373 PARAMETER_3_EMS_RM_FDBK "This signal indicates the Quickshift Assist level response from the Engine ECU in custom ride mode";
CM_ SG_ 373 PARAMETER_4_EMS_RM_FDBK "This signal indicates the Idle RPM level response from the Engine ECU in custom ride mode";
CM_ SG_ 848 HILL_MODE_STATUS "This signal indicates the hill mode is currently active during riding. Provisional for N325";
CM_ SG_ 848 ENGINE_TEMPERATURE "The temperature to retransmit only in the range of -25 ° C to 165.5 ° C.The engine temperature corresponds depending on the engine cooling water temperature or oil temperature. ";
CM_ SG_ 848 SIDE_STAND_STATUS "This signal indicates whether the side stand is on or expanded.";
CM_ SG_ 848 ENGINE_WARNING "The engine warning lamp in the dash is driven by the engine control system when errors occur can:
- Are relevant to safety
- Require a workshop visit
- Are the customers felt.";
CM_ SG_ 848 MIL_STATUS "This signal is used to control the MIL (malfunction indicator light).";
CM_ SG_ 848 GEAR_SHIFT_INDICATION "This signal gives the upshift / downshift indication.";
CM_ SG_ 848 OVER_TEMPERATURE_INDICATION "This signal indicates whether the coolant or oil temperature is too high.";
CM_ SG_ 848 ENG_ACC "Gives Engine Acceleration and deceleration values";
CM_ SG_ 848 COOLING_FAN_RELAY_STATUS "This signal indicates whether cooling fan relay is energized or not";
CM_ SG_ 848 COOLANT_TEMPERATURE "The temperature to retransmit only in the range of -25 ° C to 165.5 ° C.The engine temperature corresponds depending on the engine cooling water temperature or oil temperature. ";
CM_ SG_ 848 INJECTED_FUEL "This signal contains the accumulated amount of fuel injected. It is used to determine the average consumption and range. The signal is initialized after a reset to 0";
CM_ SG_ 848 ENGINE_ECU_ISS_STATUS "This gives various engine operating condition inside ISS
The signal is reserved in N600 project.";
CM_ SG_ 848 CYLINDER_DEACTIVATION_STATUS "This signal gives the clyinder deactivation status by EMS ECU";
CM_ SG_ 849 ENGINE_RPM_Signal_Failure "Request made by cluster to enable/disable ABS switch off functionality. 
Requires signal ABS_OFF_AVAILABILITY_STATUS to understand if rear ABS/complete ABS can be enabled/disabled";
CM_ SG_ 849 CRC_ENGINE_DATA_6 "Standard application CRC to hedge.
This signal uses the application CRC-ID = 55(Dec)  = 0x37";
CM_ SG_ 849 ALIVE_COUNTER_ENGINE_DATA_6 "Standard Protection";
CM_ SG_ 849 QSS_FEATURE_AVAILABILITY_STATUS "This signal indicated whether Quickshifter functionality is enabled or not in EMS ECU via tester tool";
CM_ SG_ 849 QSS_CLUSTER_ACTIVATION_FDBCK "This signals gives a feedback whether quickshifter functionality is enabled or disabled via cluster";
CM_ SG_ 849 KL15_STATUS "The signal indicates that the ignition key to the ON position. ";
CM_ SG_ 849 ISS_LAMP_EMS "The ISS status sent from EMS to ISG/Cluster
Indicate the status of ISS on vehicle in cluster
";
CM_ SG_ 850 INTAKE_AIR_TEMPERATURE "This signal shall transmit the intake air temperature.";
CM_ SG_ 850 MANIFOLD_AIR_PRESSURE "MAP sensor value 1 output";
CM_ SG_ 850 AMBIENT_PRESSURE "AMBIENT PRESSURE  VALUE";
CM_ SG_ 850 REDUNDANT_ODOMETER "This signal contains the redundant accumulated traverse distance of the motorcycle.";
CM_ SG_ 850 EMS_VARIANT_CODE "The value is written in EEPROM of Kombi.ABS control unit evaluates variants identifies at each control device startup. If received version of the stored variant differs, ABS control unit switches (active warning lamp, the ABS function is disabled)";
CM_ SG_ 850 OIL_PRESSURE_SWITCH_STATUS "Oil pressure switch status";
CM_ SG_ 850 MANIFOLD_AIR_PRESSURE_2 "MAP sensor value 2 output";
CM_ BO_ 851 "The message Tx will change based on the type of keyless module (integrated or separate; LF/RF or BT or RFID).
1) Separate RF unit- Tx: KEYLESS_ECU; 
2) Integrated BT unit- Tx: VCU; ";
CM_ SG_ 851 CRC_PECU_OPMSG1 "CRC-Checksum overall signals for E2E protection
This signal uses the application CRC-ID = 65 (Dec) = 0x41";
CM_ SG_ 851 ALIVE_COUNTER_PECU_OPMSG1 "Message counter for E2E protection";
CM_ SG_ 851 PECU_CLAMP_STATE "PECU Clamp state with consideration of feedback";
CM_ SG_ 851 PECU_CLAMP_STATE_STATUS "Status of the PECU Clamp State signal";
CM_ SG_ 851 IG_OFF_REQUEST "Engine OFF information to Engine ECU";
CM_ SG_ 851 ELOCK_STATE "The signal indicates the Elock state locked/unlocked";
CM_ SG_ 851 KEYLESS_SWITCH_PRESS_STATUS "The signal indicates the keyless switch short press or long press by the user. 
The signal will be reserved in case of integrated Keyless unit with cluster.";
CM_ SG_ 851 PEPSECU_ERROR_STATUS "PEPS ECU error state";
CM_ SG_ 851 CLUSTER_NOTIFICATION "Cluster notification";
CM_ BO_ 853 "The message is reserved in case of separate Keyless entry unit.";
CM_ SG_ 853 CLUSTER_SUB_ID "Subject ID i.e. Authentication Request or Reply message";
CM_ SG_ 853 CLUSTER_RESPONSE_0 "Authentication Response Byte 0";
CM_ SG_ 853 CLUSTER_RESPONSE_1 "Authentication Response Byte 1";
CM_ SG_ 853 CLUSTER_RESPONSE_2 "Authentication Response Byte 2";
CM_ SG_ 853 CLUSTER_RESPONSE_3 "Authentication Response Byte 3";
CM_ BO_ 880 "The message is reserved in N600 project";
CM_ SG_ 880 ISG_MIL_BLINK_CODE "Blink Code for ISG MIL";
CM_ SG_ 880 ISS_LAMP_ISG "The ISS status sent from ISG to EMS/Cluster
Indicate the status of ISS on vehicle in cluster
Protected for N325/N600";
CM_ SG_ 880 CRC_ISG "Standard application CRC to hedge. This signal uses the application CRC-ID = 70 (Dec) = 0x46";
CM_ SG_ 880 ALIVE_COUNTER_ISG "Standard protection!";
CM_ SG_ 880 ISG_MIL "Indicate the status of ISG MIL on cluster";
CM_ SG_ 880 ISG_ENGINE_STOP_SIG "Enable stop signal status enabled/disabled";
CM_ SG_ 880 ISG_MOTORING_STATE "Indicate the status of motoring in ISG";
CM_ SG_ 880 ISG_OPERATING_STATE "Indicate the Operaating state of ISG";
CM_ SG_ 1104 CRC_ABS_DATA_1 "Standard application CRC to hedge.
This signal uses the application CRC-ID = 35 (Dec) = 0x23";
CM_ SG_ 1104 ALIVE_COUNTER_ABS_DATA_1 "Standard protection!";
CM_ SG_ 1104 ABS_ACTUATION_STATUS "This signal tells whether ABS is actuated or not.";
CM_ SG_ 1104 BRAKE_SWITCH_STATUS_ABS "This signal indicates if the brake switch is pressed";
CM_ SG_ 1104 BRAKE_PAD_PRESSURE_FRONT "This signal indicates the front brake pad pressure value";
CM_ SG_ 1104 DISTANCE_FRONT "This signal contains the cumulative distance of the speed sensor on the front wheel. After reaching 999.75 m the signal should start again at 0 - an overflowing of the counter corresponds exactly 1km.
";
CM_ SG_ 1104 DISTANCE_REAR "This signal contains the cumulative distance of the speed sensor on the rear wheel. After reaching 999.75 m the signal should start again at 0 - an overflowing of the counter corresponds exactly 1km.";
CM_ SG_ 1104 ABS_ON_OFF_SET_FDBK "This signal gives status if whether ABS is turned ON or OFF by HECU";
CM_ SG_ 1104 ABS_OFF_FEATURE_AVAIL_STATUS "This signal displays the availability of feature to turn off ABS in cluster.
If this is enabled, then menu option to disable ABS will be enabled";
CM_ SG_ 1104 BRAKE_PAD_PRESSURE_REAR "This signal indicates the rear brake pad pressure value";
CM_ SG_ 1105 CRC_SPEED "Standard application CRC to hedge.
This signal uses the application CRC-ID = 20 (Dec) = 0x14";
CM_ SG_ 1105 ALIVE_COUNTER_SPEED "Standard protection!";
CM_ SG_ 1105 WHEEL_SPEED_REAR "This signal contains the speed of the rear wheel in km / h.";
CM_ SG_ 1105 WHEEL_SPEED_FRONT "This signal contains the speed of the front wheel in km / h.";
CM_ SG_ 1105 WHEEL_SPEED_REAR_STATUS "This signal indicates the status of the rear speed sensor.
";
CM_ SG_ 1105 WHEEL_SPEED_FRONT_STATUS "This signal indicates the status of the front speed sensor.";
CM_ SG_ 1105 LC_STATUS "The signal indicates the status of the Launch control by ABS unit";
CM_ SG_ 1105 NUMBER_OF_LAUNCHES "The signal indicates the number of launches happened in particular ignition or launch cycle.";
CM_ SG_ 1105 ABS_STATUS "It is used by Insturment cluster  for controlling the ABS warning lamp,


";
CM_ SG_ 1105 RESERVED_SIGNAL "Reserved signal from Other project (U388)";
CM_ SG_ 1105 WHEEL_ACC "Gives vehicle Acceleration and deceleration values";
CM_ BO_ 1109 "Feature enable Signal";
CM_ SG_ 1109 CRC_ABS_FEATURE_EN "Standard application CRC to hedge.
This signal uses the application CRC-ID = 63(Dec)  = 0x3F";
CM_ SG_ 1109 ALIVE_COUNTER_ABS_FEATURE_EN "Standard Protection";
CM_ SG_ 1109 FEATURE_EN_RLP "Enable or disable Rear Lift Off Protection feature";
CM_ SG_ 1109 FEATURE_EN_SDC "Enable or disable Slope Dependent control feature";
CM_ SG_ 1109 FEATURE_EN_MLC "Enable or disable Motorcycle launch feature";
CM_ SG_ 1109 FEATURE_EN_WC "Enable or disable Wheelie Control feature";
CM_ SG_ 1109 FEATURE_EN_IMU "Enable or disable IMU feature";
CM_ SG_ 1109 FEATURE_EN_DTC "Enable or disable Drag Traction Control feature";
CM_ SG_ 1360 TIMER_SECONDS "This counter counts in synchronization with the system / clock the seconds. This signal relative times can be measured. The signal counts in seconds scanning from 0 to about 16 million, which is about 194 days.";
CM_ SG_ 1360 ODO_CLUSTER "This signal contains the total distance covered by the motorcycle.";
CM_ SG_ 1360 CLUSTER_VARIANT_CODE "This signal gives the details of the SW features that the cluster SW supports";
CM_ SG_ 1360 ABS_VEH_CODE "This signal gives the details of the SW features that the cluster SW supports";
CM_ SG_ 1360 HORN_ENABLE_IP "The signal is to enable/disable horn output to VCU";
CM_ SG_ 1360 HEATED_GRIP_LEVEL_IP "Heated grip level input from speedo to VCU";
CM_ SG_ 1360 PRECONDITION_STAT_SPEEDO "This signal is a status indicating pre-conditioning active";
CM_ SG_ 1361 VEHICLE_BATTERY_VOLTAGE "This signal indicates the battery voltage as seen be Cluster ECU";
CM_ BO_ 1184 "The message is for debud purpose - ABS unit. 
It will be enabled when DID is enabled to send debug frames.";
CM_ SG_ 1184 TC_ACTIVATION_REASON "Indicates reason for activation of TC.";
CM_ SG_ 1184 CORNERING_ABS_STATUS "This signal displays the activation status of cornering ABS by HECU";
CM_ SG_ 1184 ABS_ACTUATION_DEBUG "This signal provides reason for ABS if actuated.";
CM_ SG_ 1184 WHEEL_SLIP_PERCENTAGE "Indicates percentage of difference between surface speed of the wheel and actual speed of vehicle";
CM_ BO_ 2016 "The message is for tester communication (debug message)";
CM_ SG_ 2016 TESTER_REQUEST_EMS "The signal is used as communication between tester tool and cluster unit.";
BA_DEF_  "DBName" STRING ;
BA_DEF_  "BusType" STRING ;
BA_DEF_  "Manufacturer" STRING ;
BA_DEF_ BO_  "GenMsgSendType" ENUM  "Cyclic","Spontaneous","vector_leerstring";
BA_DEF_ BO_  "GenMsgCycleTime" INT 0 1000000;
BA_DEF_ SG_  "SystemSignalLongSymbol" STRING ;
BA_DEF_DEF_  "DBName" "";
BA_DEF_DEF_  "BusType" "";
BA_DEF_DEF_  "Manufacturer" "TVSM";
BA_DEF_DEF_  "GenMsgSendType" "Cyclic";
BA_DEF_DEF_  "GenMsgCycleTime" 100;
BA_DEF_DEF_  "SystemSignalLongSymbol" "";
BA_ "BusType" "CAN";
BA_ "DBName" "Database_v2_2";
BA_ "GenMsgSendType" BO_ 2017 1;
BA_ "GenMsgCycleTime" BO_ 2017 0;
BA_ "GenMsgSendType" BO_ 2025 1;
BA_ "GenMsgCycleTime" BO_ 2025 0;
BA_ "GenMsgSendType" BO_ 2024 1;
BA_ "GenMsgCycleTime" BO_ 2024 0;
BA_ "GenMsgCycleTime" BO_ 256 0;
BA_ "GenMsgSendType" BO_ 256 1;
BA_ "GenMsgCycleTime" BO_ 258 0;
BA_ "GenMsgSendType" BO_ 258 1;
BA_ "GenMsgCycleTime" BO_ 288 10;
BA_ "GenMsgCycleTime" BO_ 320 20;
BA_ "GenMsgCycleTime" BO_ 336 10;
BA_ "GenMsgCycleTime" BO_ 337 20;
BA_ "GenMsgCycleTime" BO_ 352 10;
BA_ "GenMsgCycleTime" BO_ 368 10;
BA_ "GenMsgCycleTime" BO_ 372 10;
BA_ "GenMsgCycleTime" BO_ 376 10;
BA_ "GenMsgCycleTime" BO_ 380 10;
BA_ "GenMsgCycleTime" BO_ 851 50;
BA_ "GenMsgCycleTime" BO_ 880 10;
BA_ "GenMsgCycleTime" BO_ 1104 50;
BA_ "GenMsgCycleTime" BO_ 1105 50;
BA_ "GenMsgCycleTime" BO_ 1109 1000;
BA_ "GenMsgCycleTime" BO_ 1361 1000;
BA_ "GenMsgCycleTime" BO_ 1184 10;
BA_ "GenMsgCycleTime" BO_ 2016 0;
BA_ "GenMsgSendType" BO_ 2016 1;
BA_ "SystemSignalLongSymbol" SG_ 3221225472 CC_TORQUE_REQ_STATUS_ENG_FB_Copy "CC_TORQUE_REQ_STATUS_ENG_FB_Copy_1";
VAL_ 3221225472 CC_TORQUE_REQ_STATUS_ENG_FB_Copy 2 "Invalid or cannot be met" 1 "CC control Active" 0 "No control" ;
VAL_ 3221225472 DNP_IMMOBILIZER_LAMP_INDICATION 0 "Lamp OFF" 1 "Lamp ON" ;
VAL_ 3221225472 DNP_HEADLAMP_STATUS 0 "Headlamp OFF" 1 "Headlamp ON" ;
VAL_ 3221225472 HEATED_GRIP_FEAT_EN 0 "Feature not available" 1 "Feature available" ;
VAL_ 3221225472 HAPTIC_GRIP_FEAT_EN 0 "Feature not available" 1 "Feature available" ;
VAL_ 3221225472 WINDSHIELD_FEAT_EN 0 "Feature not available" 1 "Feature available" ;
VAL_ 3221225472 KEYLESS_FEAT_EN 0 "Feature not available" 1 "Feature available" ;
VAL_ 3221225472 CLIMATIC_SEAT_FEAT_EN 0 "Feature not available" 1 "Feature available" ;
VAL_ 3221225472 HOT_SEAT_FEAT_EN 0 "Feature not available" 1 "Feature available" ;
VAL_ 3221225472 FEATURE_EN_LC 0 "Disabled" 1 "Enabled" ;
VAL_ 1488 TEMPERATURE_AMBIENT 102 "Out of range" 101 "Signal Invalid" ;
VAL_ 1488 TEMPERATURE_PELTIER1 102 "Out of range" 101 "Signal Invalid" ;
VAL_ 1488 TEMPERATURE_PELTIER2 102 "Out of range" 101 "Signal Invalid" ;
VAL_ 1488 SEAT_ERROR 15 "Invalid" 6 "Abnormal supply voltage" 5 "error in control module" 4 "thermistor failure" 3 "error in fan" 2 "peltier not working" 0 "no error" 1 "mode not supported" ;
VAL_ 1488 COOLSEAT_FEATURE_ACK 2 "Invalid" 0 "Feature not enabled on vehicle" 1 "feature enablled on vehicle" ;
VAL_ 1488 REQUESTED_LEVEL 31 "Reserved" 17 "cold level 3" 16 "cold level 2" 15 "cold level 1" 4 "reserved" 3 "Hot level 3" 2 "Hot level 2" 0 "Off" 1 "Hot level 1" ;
VAL_ 1489 COOLSEAT_FEATURE_EN 2 "Invalid" 0 "Feature not enabled on vehicle" 1 "feature enablled on vehicle" ;
VAL_ 1489 TARGET_LEVEL 31 "Reserved" 17 "cold level 3" 16 "cold level 2" 15 "cold level 1" 4 "reserved" 3 "Hot level 3" 2 "Hot level 2" 0 "Off" 1 "Hot level 1" ;
VAL_ 852 KEYFOB_LOWBATTERY_WARN 0 "Keyfob battery normal" 1 "Keyfob battery Low" ;
VAL_ 852 NO_KEYFOB_DETECTED_WARN 0 "Keyfob detected" 1 "No keyfob detected" ;
VAL_ 1400 CORNER_LAMP_L2_CTRL 3 "Invalid" 2 "RH Lamp ON" 1 "LH lamp ON" 0 "No Lamp On/lamp Off" ;
VAL_ 1400 CORNER_LAMP_L1_CTRL 3 "Invalid" 2 "RH Lamp ON" 1 "LH lamp ON" 0 "No Lamp On/lamp Off" ;
VAL_ 1400 HL_ERR_STATUS 7 "Reserved" 6 "Reserved" 5 "DRL/POS Failure" 4 "LB Failure" 3 "HB Failure" 2 "Overvoltage Protection" 1 "Undervoltage Protection" 0 "No Error" ;
VAL_ 1400 DYNAMIC_INTENSITY_LEVEL_FDBK 3 "Reserved" 2 "Level 3" 1 "Level 2" 0 "Default/level1" ;
VAL_ 1400 HL_DAY_NIGHT_MODE_FDBK 1 "Day/DRL ON/Headlamp Off" 0 "Night/ DRL OFF/ Headlamp ON" ;
VAL_ 1400 HL_BEAM_STATUS 1 "HB ON" 0 "HB OFF/LB Only" ;
VAL_ 1400 DRL_PATTERN_EXEC_STATUS 1 "Executed" 0 "Not Executed" ;
VAL_ 1400 DRL_PATTERN_FDBK 15 "Reserved" 3 "Reserved" 2 "Pattern 2" 1 "Pattern 1" 0 "Normal/NoPattern" ;
VAL_ 1392 FOG_LAMP_CONTROL_LH 1 "Lamp On" 0 "Lamp Off" ;
VAL_ 1392 HL_BEAM_CONTROL 1 "HB ON" 0 "HB OFF/LB Only" ;
VAL_ 1392 FOG_LAMP_CONTROL_RH 1 "Lamp On" 0 "Lamp Off" ;
VAL_ 1392 BEND_LAMP_EN 1 "Enable" 0 "Disable" ;
VAL_ 1392 HL_DAY_NIGHT_MODE 1 "Day/DRL ON/Headlamp Off" 0 "Night/ DRL OFF/ Headlamp ON" ;
VAL_ 1392 DYNAMIC_HB_CTRL_MODE 1 "Auto Mode" 0 "Manual Mode" ;
VAL_ 1392 HL_CTRL_MODE 1 "Auto Mode" 0 "Manual Mode" ;
VAL_ 1392 DYNAMIC_INTENSITY_LEVEL_SET 3 "Reserved" 2 "Level 3" 1 "Level 2" 0 "Default/level1" ;
VAL_ 1392 HL_FOLLOW_ME_HOME_SET 3 "Level 3" 2 "Level 2" 1 "Level 1" 0 "OFF" ;
VAL_ 1392 ALIVE_COUNTER_HEADLAMP_CONTROL 15 "Signal invalid" ;
VAL_ 256 PECU_SUB_ID 0 "Default" 1 "Authentication request" 2 "Reply message" 3 "Reserved" ;
VAL_ 258 VEHICLE_ECU_SUB_ID 0 "Default" 1 "Random number" 2 "Authentication result" 3 "Reserved" ;
VAL_ 258 VEHICLE_ECU_AUTH_RESULT 0 "Successful" 1 "Failed" 2 "Reserved" ;
VAL_ 288 ALIVE_COUNTER_QS_CC_TC_SETTING 15 "Signal invalid" ;
VAL_ 288 FRONT_VEHICLE_BRAKE_STATUS 3 "Signal Invalid" 2 "Brake Sw. not actuated" 1 "Brake Sw. actuated" 0 "Defective switch" ;
VAL_ 288 CRUISE_CONTROL_ON_OFF 0 "Switch not pressed" 1 "Switch pressed" 2 "Switch defective" 3 "Signal invalid" ;
VAL_ 288 DISPLAY_SPEED 4095 "Signal invalid" ;
VAL_ 288 CRUISE_CONTRL_SET_MINUS 0 "Switch not pressed" 1 "Switch pressed" 2 "Switch defective" 3 "Signal invalid" ;
VAL_ 288 CRUISE_CONTRL_RESET_PLUS 0 "Switch not pressed" 1 "Switch pressed" 2 "Switch Defective" 3 "Signal invalid" ;
VAL_ 288 DISPLAY_SPEED_UNIT 0 "Reserved" 1 "kmph" 2 "miles per hour" 3 "Signal invalid" ;
VAL_ 288 DTC_ENABLE_STATUS_CLUSTER 1 "DTC ON" 0 "DTC OFF" ;
VAL_ 288 TC_ENABLE_STATUS_CLUSTER 1 "TC ON" 0 "TC OFF" ;
VAL_ 288 LC_ENABLE_STATUS_CLUSTER 1 "LC ON" 0 "LC OFF" ;
VAL_ 288 QSS_CLUSTER_ACTIVATION 1 "QS Active" 0 "QS not active" ;
VAL_ 288 TC_INTERVENTION_SETTING 0 "Reserve" 1 "LEVEL 1" 2 "LEVEL 2" 3 "LEVEL 3" 4 "LEVEL 4" 5 "Reserve" 6 "Reserve" 7 "Signal invalid" ;
VAL_ 288 REAR_BRAKE_SWITCH_STATUS 3 "Signal Invalid" 2 "Brake Sw. not actuated" 1 "Brake Sw. actuated" 0 "Defective switch" ;
VAL_ 293 ISS_IC 0 "ISS OFF" 1 "ISS ON" ;
VAL_ 293 ALIVE_COUNTER_CLUSTER_SETTING 15 "Signal invalid" ;
VAL_ 293 ENG_RIDING_MODE_SET 7 "Signal invalid" 6 "Reserve" 5 "Reserve" 4 "Custom" 3 "Level 3" 2 "Level 2" 1 "Level 1" 0 "Reserve" ;
VAL_ 293 ABS_RIDING_MODE_SET 0 "Reserve" 1 "Race" 2 "Normal" 3 "Wet" 4 "SM_RearABSOff" 5 "Custom" 6 "Reserve" 7 "Signal invalid" ;
VAL_ 293 VEHICLE_RIDING_MODE_SET 0 "Reserve" 1 "Race (Race+Race)" 2 "Street(Race+Normal)" 3 "Rain(City+Wet)" 4 "City(City+Normal)" 5 "SM(Race+SM)" 6 "Custom mode" 7 "Signal invalid" ;
VAL_ 293 TC_RIDING_MODE_SET 7 "INVALID" 6 "Reserve" 5 "Reserve" 4 "Level 4" 3 "Level 3" 2 "Level 2" 1 "Level 1" 0 "Reserved" ;
VAL_ 293 ISG_BOOST_SET 7 "Signal invalid" 6 "Reserve" 5 "Reserve" 4 "Reserve" 3 "Reserve" 2 "Reserve" 1 "Reserve" 0 "Reserve" ;
VAL_ 293 IG_OFF_ACK 0 "Switch off ignition" 1 "Do not switch off ignition" 2 "Virtual ignition ON (ES disabled)" 3 "Signal invalid" ;
VAL_ 293 ABS_ON_OFF_SET 0 "TURN ON ABS" 1 "TURN OFF ABS" ;
VAL_ 294 ALIVE_COUNTER_SUB_RM_PARAMS 15 "Signal invalid" ;
VAL_ 294 PARAMETER_1_EMS 7 "Signal invalid" 6 "Reserve" 5 "Level 5" 4 "Level 4" 3 "Level 3" 2 "Level 2" 1 "Level 1" 0 "Reserve" ;
VAL_ 294 PARAMETER_2_EMS 7 "Signal invalid" 6 "Reserve" 5 "Reserve" 4 "Reserve" 3 "Level 3" 2 "Level 2" 1 "Level 1" 0 "Reserve" ;
VAL_ 294 PARAMETER_3_EMS 3 "Signal invalid" 2 "Level 2" 1 "Level 1" 0 "Reserve" ;
VAL_ 294 PARAMETER_4_EMS 3 "Signal invalid" 2 "Level 3" 1 "Level 2" 0 "Level 1" ;
VAL_ 294 PARAMETER_2_ABS 7 "Signal invalid" 6 "Reserve" 5 "Reserve" 4 "Reserve" 3 "Level 3" 2 "Level 2" 1 "Level 1" 0 "Reserve" ;
VAL_ 294 PARAMETER_1_ABS 7 "Signal invalid" 6 "Reserve" 5 "Reserve" 4 "Level 4" 3 "Level 3" 2 "Level 2" 1 "Level 1" 0 "Reserve" ;
VAL_ 320 ALIVE_COUNTER_TRACTION_CONTROL 15 "Signal invalid" ;
VAL_ 320 NOTUSE_TRACTION_CONTRL_MODE_FB 0 "Mode 1" 1 "Mode 2" 2 "Mode 3" 3 "Invalid" ;
VAL_ 320 TC_FEATURE_AVAILABILITY_STATUS 0 "TC Not available" 1 "TC available" ;
VAL_ 320 TARGET_CLUTCH_TORQUE_REQ 1023 "Signal invalid" ;
VAL_ 320 TORQUE_REQ_STATUS 3 "Invalid" 2 "DTC" 1 "MTC" 0 "No control" ;
VAL_ 320 QSS_ENABLE_DISABLE_ABS 2 "RESERVED" 3 "INVALID" 1 "ENABLE" 0 "DISABLE" ;
VAL_ 320 TC_MODE_CONDITION_STATUS 0 "Condition for mode change not met" 1 "Condtion for mode change  met" ;
VAL_ 320 TRACTION_CONTROL_STATUS 0 "TC NOT ACTIVE" 1 "TC ACTIVE INTERVENTION" 2 "TC ERROR" 3 "TC INTIALIZING" 4 "TC DISABLED BY RIDER" 6 "Cornering TC is not working" 7 "Signal invalid" ;
VAL_ 320 TC_INTERVENTION_SETTING_FDBK 0 "Reserve" 1 "LEVEL 1" 2 "LEVEL 2" 3 "LEVEL 3" 4 "LEVEL 4" 5 "Reserve" 6 "Reserve" 7 "Signal invalid" ;
VAL_ 320 ODO_ABS 1048575 "Signal invalid" ;
VAL_ 320 DTC_FEATURE_AVAILABILITY_STATUS 0 "DTC Not available" 1 "DTC available" ;
VAL_ 336 ALIVE_COUNTER_ENGINE_DATA_1 15 "Signal invalid" ;
VAL_ 336 HANDLE_GRIP_OPEN_PERCENTAGE_1 255 "Signal invalid" ;
VAL_ 336 CLUTCH_SW_STATUS 0 "Clutch Sw. Not pressed" 1 "Clutch Sw. pressed fully" 2 "Clutch sw pressed partially" 3 "Signal invalid/Clutch failure" ;
VAL_ 336 THROTTLE_OPEN_PERCENTAGE_1 255 "Signal invalid" ;
VAL_ 336 GEAR_POSITION 0 "Reverse Gear" 1 "1 Gear" 2 "Nuetral" 3 "Parking" 4 "2 Gear" 5 "Forward gear" 6 "Reserved " 7 "3 Gear" 8 "4 Gear" 9 "Reserve" 10 "Reserve" 11 "5 Gear" 12 "Reserve" 13 "6 Gear" 14 "Reserve" 15 "Signal invalid" ;
VAL_ 336 ENGINE_RPM 16383 "Signal invalid" ;
VAL_ 336 KILL_STATUS 0 "Kill OFF" 1 "Kill ON" 2 "Reserved" 3 "Signal invalid" ;
VAL_ 336 ES_SWITCH_STATUS 0 "ES switch not pressed" 1 "ES switch pressed" 2 "Reserved" 3 "Signal invalid" ;
VAL_ 336 KL50_STATUS 0 "Relay not activated" 1 "Relay activated" 2 "Reserved" 3 "Signal invalid" ;
VAL_ 336 CLUTCH_SW_STATUS_2 0 "Clutch sw 2 Not pressed" 1 "Clutch sw 2 pressed fully" 2 "Clutch sw 2 pressed partially" 3 "Signal invalid/Clutch sw 2 failure" ;
VAL_ 337 ALIVE_COUNTER_ENGINE_DATA_5 15 "Signal invalid" ;
VAL_ 337 TORQUE_REQ_STATUS_ENG_FB 3 "Invalid" 2 "DTC" 1 "MTC" 0 "No control" ;
VAL_ 337 ENGINE_STATUS 0 "Running" 1 "CRANKING" 2 "Stalled" 3 "Invalid" ;
VAL_ 337 ACTUAL_ENG_TORQUE 1023 "Signal invalid" ;
VAL_ 337 QS_UPSHIFT_STATUS_TC 1 "Upshift" 0 "No Upshift" ;
VAL_ 337 QS_DOWNSHIFT_STATUS_TC 1 "Downshift" 0 "No Downshift" ;
VAL_ 337 DRIVER_REQ_TORQUE 1023 "Signal invalid" ;
VAL_ 337 MINIMUM_ENG_TORQUE 1023 "Signal invalid" ;
VAL_ 337 MAXIMUM_ENG_TORQUE 1023 "Signal invalid" ;
VAL_ 337 ENGINE_TORQUE_EXCECUTION 4 "QS functional" 3 "CC torque from HECU" 2 "TC torque from HECU" 1 "Driver req torque" 0 "No operation" ;
VAL_ 352 ALIVE_COUNTER_ABS_CRUISE_CONTROL 15 "Signal invalid" ;
VAL_ 352 CRUISE_DEACTIVATION_CONDITION 15 "Signal Invalid" 14 "No deactivation input" 13 "Reserved" 12 "Reserved" 11 "Reserved" 10 "OTHER ERRORS" 9 "THROTTLE BLIP" 8 "MIL" 7 "MULTIPLE GEAR SHIFTS" 6 "VEHICLE ACC/ DECELERATION" 5 "WHEEL SLIP " 4 "CRUISE BUTTON OFF" 3 "RIDE MODE CHANGE" 2 "GEAR CHANGE" 1 "CLUTCH PRESSED" 0 "BRAKES PRESSED" ;
VAL_ 352 CC_FEATURE_AVAILABILITY_STATUS 1 "CC AVAILABLE" 0 "CC NOT AVAILABLE" ;
VAL_ 352 CRUISE_CONTROL_STATUS 5 "CC  ERROR_FAILURE" 0 "CC NOT ACTIVE" 1 "CC  STAND BY" 2 "CC CRUISE" 3 "CC SUSPEND" 4 "CC TAKE CONTROL" 7 "Signal invalid" ;
VAL_ 352 TARGET_CRUISE_SPEED 4095 "Signal invalid" ;
VAL_ 352 TARGET_TORQUE_REQUEST_CC 2 "Invalid or cannot be met" 1 "CC control Active" 0 "No control" ;
VAL_ 352 TARGET_CRUISE_TORQUE 1023 "Signal invalid" ;
VAL_ 357 ALIVE_COUNTER_ABS_DATA_2 15 "Signal invalid" ;
VAL_ 357 WHEELIE_ANGLE 2047 "Signal Invalid" ;
VAL_ 357 RIDE_MODE_ABS_CONDITION_STATUS 0 "Codition for mode change not met" 1 "Condtion for mode change  met" ;
VAL_ 357 LEAN_ANGLE 2047 "Signal Invalid" ;
VAL_ 357 RIDING_MODE_ABS_FEEDBACK 0 "Reserve" 1 "Race" 2 "Normal" 3 "Wet" 4 "SM_RearABSOff" 5 "Custom" 6 "Reserve" 7 "Signal invalid" ;
VAL_ 357 SKID_ANGLE 2047 "Signal Invalid" ;
VAL_ 357 RIDE_MODE_ABS_ERROR_STATUS 0 "No Ride Mode Error in EMS" 1 "Ride Mode Error present in EMS" ;
VAL_ 357 VEHICLE_RIDEMODE_ABS_FDBK 0 "Reserve" 1 "Race (Race+Race)" 2 "Street(Race+Normal)" 3 "Rain(City+Wet)" 4 "City(City+Normal)" 5 "SM(Race+SM)" 6 "Custom mode" 7 "Signal invalid" ;
VAL_ 357 IMU_STATUS 0 "No Error" 1 "IMU Error" 2 "Other" 3 "Invalid" ;
VAL_ 357 ROLL_OVER_OUTPUT 0 "Roll over cut-off inactive" 1 "Roll over cut-off active" ;
VAL_ 357 ABS_VARIANT_CODE 255 "SIGNAL INVALID" 0 "QS=0,CC=0,TC=0,DTC=0" 1 "QS=0,CC=0,TC=1,DTC=0" 2 "QS=0,CC=1,TC=0,DTC=0" 3 "QS=0,CC=1,TC=1,DTC=0" 4 "QS=1,CC=0,TC=0,DTC=0" 5 "QS=1,CC=0,TC=1,DTC=0" 6 "QS=1,CC=1,TC=0,DTC=0" 7 "QS=1,CC=1,TC=1,DTC=0" 8 "QS=0,CC=0,TC=0,DTC=1" 9 "QS=0,CC=0,TC=1,DTC=1" 10 "QS=0,CC=1,TC=0,DTC=1" 11 "QS=0,CC=1,TC=1,DTC=1" 12 "QS=1,CC=0,TC=0,DTC=1" 13 "QS=1,CC=0,TC=1,DTC=1" 14 "QS=1,CC=1,TC=0,DTC=1" 15 "QS=1,CC=1,TC=1,DTC=1" ;
VAL_ 358 TC_RIDING_MODE_FDBK 7 "INVALID" 6 "Reserve" 5 "Reserve" 4 "Level 4" 3 "Level 3" 2 "Level 2" 1 "Level 1" 0 "Reserved" ;
VAL_ 358 ALIVE_COUNTER_ABS_RM_PARAM_FDBK 15 "Signal invalid" ;
VAL_ 358 PARAMETER_1_ABS_RM_FDBK 7 "Signal invalid" 6 "Reserve" 5 "Reserve" 4 "Level 4" 3 "Level 3" 2 "Level 2" 1 "Level 1" 0 "Reserve" ;
VAL_ 358 PARAMETER_2_ABS_RM_FDBK 7 "Signal invalid" 6 "Reserve" 5 "Reserve" 4 "Reserve" 3 "Level 3" 2 "Level 2" 1 "Level 1" 0 "Reserve" ;
VAL_ 368 ALIVE_COUNTER_ENGINE_DATA_4 15 "Signal invalid" ;
VAL_ 373 TPS_ERROR_ST 0 "No TPS Error" 1 "TPS Error Present" ;
VAL_ 373 ALIVE_COUNTER_ENGINE_DATA_3 15 "Signal invalid" ;
VAL_ 373 RIDE_MODE_ENG_CONDITION_STATUS 0 "Condition mode change not met" 1 "Condtion for mode change met" ;
VAL_ 373 ENG_RIDING_MODE_FEEDBACK 7 "Signal invalid" 6 "Reserve" 5 "Reserve" 4 "Custom" 3 "Level 3" 2 "Level 2" 1 "Level 1" 0 "Reserve" ;
VAL_ 373 RIDE_MODE_ENG_ERROR_STATUS 0 "No Ride Mode Error in EMS" 1 "Ride Mode Error present in EMS" ;
VAL_ 373 VEHICLE_RIDEMODE_ENG_FDBK 0 "Reserve" 1 "Race (Race+Race)" 2 "Street(Race+Normal)" 3 "Rain(City+Wet)" 4 "City(City+Normal)" 5 "SM(Race+SM)" 6 "Custom mode" 7 "Signal invalid" ;
VAL_ 373 THROTTLE_OPEN_PERCENTAGE_2 255 "Signal invalid" ;
VAL_ 373 HANDLE_GRIP_OPEN_PERCENTAGE_2 255 "Signal invalid" ;
VAL_ 373 PARAMETER_1_EMS_RM_FDBK 7 "Signal invalid" 6 "Reserve" 5 "Level 5" 4 "Level 4" 3 "Level 3" 2 "Level 2" 1 "Level 1" 0 "Reserve" ;
VAL_ 373 PARAMETER_2_EMS_RM_FDBK 7 "Signal invalid" 6 "Reserve" 5 "Reserve" 4 "Reserve" 3 "Level 3" 2 "Level 2" 1 "Level 1" 0 "Reserve" ;
VAL_ 373 PARAMETER_3_EMS_RM_FDBK 3 "Signal invalid" 2 "Level 2" 1 "Level 1" 0 "Reserve" ;
VAL_ 373 PARAMETER_4_EMS_RM_FDBK 4 "Signal invalid" 2 "Level 3" 1 "Level 2" 0 "Level 1" ;
VAL_ 848 HILL_MODE_STATUS 0 "HILL Mode Not Active" 1 "HILL Mode Active" ;
VAL_ 848 ENGINE_TEMPERATURE 255 "Signal invalid" ;
VAL_ 848 SIDE_STAND_STATUS 0 "Side stand switch defective" 1 "Side stand retracted" 2 "Side stand out" 3 "Signal invalid" ;
VAL_ 848 ENGINE_WARNING 0 "Warning ON" 1 "Warning OFF" ;
VAL_ 848 MIL_STATUS 0 "MIL OFF" 1 "MIL ON" ;
VAL_ 848 RUNNING_IN_MODE_STATUS 0 "Running In mode Enabled" 1 "Running in mode disabled" 2 "Reserve" 3 "Signal invalid" ;
VAL_ 848 GEAR_SHIFT_INDICATION 0 "Gear Shift Indication Down ON" 1 "Gear Shift Indication Up ON" 2 "Gear Shift Indication OFF" 3 "Signal invalid" ;
VAL_ 848 OVER_TEMPERATURE_INDICATION 0 "Warning OFF" 1 "Warning ON" ;
VAL_ 848 COOLING_FAN_RELAY_STATUS 0 "Cooling Fan relay OFF" 1 "Cooling Fan relay ON" ;
VAL_ 848 COOLANT_TEMPERATURE 255 "Signal invalid" ;
VAL_ 848 INJECTED_FUEL 65535 "Signal invalid" ;
VAL_ 848 ENGINE_ECU_ISS_STATUS 0 "Engine run/stop due to normal operation" 1 "Veh stop due to ISS condition" 2 "Veh start request due to ISS condition" 3 "ISS disable due to condition not met" ;
VAL_ 848 CYLINDER_DEACTIVATION_STATUS 0 "No cylinder deactivated" 1 "Single cylinder deactivated" 2 "Reserved" 3 "All cylinders deactivated" ;
VAL_ 849 ENGINE_RPM_Signal_Failure 0 "No Error in Signal" 1 "Signal Error" ;
VAL_ 849 ES_INHIBIT 0 "Dont Allow ES Function" 1 "Allow ES function" ;
VAL_ 849 ALIVE_COUNTER_ENGINE_DATA_6 15 "Signal invalid" ;
VAL_ 849 QSS_FEATURE_AVAILABILITY_STATUS 3 "Signal Invalid" 2 "QS Available with error" 1 "QS Available" 0 "QS Not available" ;
VAL_ 849 QSS_CLUSTER_ACTIVATION_FDBCK 1 "Active" 0 "Not Active" ;
VAL_ 849 KL15_STATUS 0 "KL 15 OFF" 1 "KL 15 ON" 2 "Reserved" 3 "Signal invalid" ;
VAL_ 849 ISS_LAMP_EMS 0 "Lamp OFF" 1 "Lamp blink" 2 "Lamp ON" 3 "Reserved" ;
VAL_ 850 INTAKE_AIR_TEMPERATURE 255 "Signal invalid" ;
VAL_ 850 MANIFOLD_AIR_PRESSURE 255 "Signal invalid" ;
VAL_ 850 AMBIENT_PRESSURE 1023 "Signal invalid" ;
VAL_ 850 REDUNDANT_ODOMETER 1048575 "Signal invalid" ;
VAL_ 850 EMS_VARIANT_CODE 255 "SIGNAL INVALID" 0 "QS=0,CC=0,TC=0,DTC=0" 1 "QS=0,CC=0,TC=1,DTC=0" 2 "QS=0,CC=1,TC=0,DTC=0" 3 "QS=0,CC=1,TC=1,DTC=0" 4 "QS=1,CC=0,TC=0,DTC=0" 5 "QS=1,CC=0,TC=1,DTC=0" 6 "QS=1,CC=1,TC=0,DTC=0" 7 "QS=1,CC=1,TC=1,DTC=0" 8 "QS=0,CC=0,TC=0,DTC=1" 9 "QS=0,CC=0,TC=1,DTC=1" 10 "QS=0,CC=1,TC=0,DTC=1" 11 "QS=0,CC=1,TC=1,DTC=1" 12 "QS=1,CC=0,TC=0,DTC=1" 13 "QS=1,CC=0,TC=1,DTC=1" 14 "QS=1,CC=1,TC=0,DTC=1" 15 "QS=1,CC=1,TC=1,DTC=1" ;
VAL_ 850 OIL_PRESSURE_SWITCH_STATUS 0 "Switch closed" 1 "Switch open" 2 "Reserved" 3 "Signal invalid" ;
VAL_ 850 MANIFOLD_AIR_PRESSURE_2 255 "Signal invalid" ;
VAL_ 851 ALIVE_COUNTER_PECU_OPMSG1 15 "Signal Invalid" ;
VAL_ 851 PECU_CLAMP_STATE 0 "OFF" 1 "IGN ON" 2 "CRANK ON (Engine ON)" 3 "RUN (Engine RUN)" 4 "Reserved" 5 "Reserved" 6 "Reserved" 7 "Reserved" ;
VAL_ 851 PECU_CLAMP_STATE_STATUS 0 "Valid / Default" 1 "invalid" ;
VAL_ 851 IG_OFF_REQUEST 0 "No Action" 1 "Ignition OFF" 2 "IG Off Wait For acknowledgement" 3 "Signal Invalid" ;
VAL_ 851 ELOCK_STATE 0 "Error State" 1 "Locked" 2 "UnLocked" 3 "Invalid" ;
VAL_ 851 KEYLESS_SWITCH_PRESS_STATUS 0 "Keyless switch short press" 1 "Keyless switch long press" 2 "Keyless switch very long press" 3 "keyless switch error" 4 "Reserved" 5 "Reserved" 6 "Reserved" 7 "Signal Invalid" ;
VAL_ 851 PEPSECU_ERROR_STATUS 0 "No Error present" 1 "Error present" ;
VAL_ 851 CLUSTER_NOTIFICATION 0 "Notification Off" 1 "Notification ON" ;
VAL_ 853 CLUSTER_SUB_ID 0 "Default" 1 "Authentication request" 2 "Reply message" 3 "Reserved" ;
VAL_ 880 ISG_MIL_BLINK_CODE 255 "Signal Invalid" ;
VAL_ 880 ISS_LAMP_ISG 0 "Lamp OFF" 1 "Lamp Blink" 2 "Lamp ON" ;
VAL_ 880 ALIVE_COUNTER_ISG 15 "Signal invalid" ;
VAL_ 880 ISG_BOOST_CONDN_STATUS 0 "Not Achieved" 1 "Achieved" ;
VAL_ 880 BOOST_MODE_ISG_FB 7 "Signal invalid" 6 "Reserve" 5 "Reserve" 4 "Reserve" 3 "Reserve" 2 "Reserve" 1 "Reserve" 0 "Reserve" ;
VAL_ 880 ISG_BOOST_ERROR_STATUS 0 "No error" 1 "Error" ;
VAL_ 880 VEH_RM_ISG_FB 0 "Reserve" 1 "Race (Race+Race)" 2 "Street(Race+Normal)" 3 "Rain(City+Wet)" 4 "City(City+Normal)" 5 "SM(Race+SM)" 6 "Reserve" 7 "Signal invalid" ;
VAL_ 880 ISG_MIL 0 "Lamp OFF" 1 "Lamp ON" ;
VAL_ 880 ISG_ENGINE_STOP_SIG 0 "ISG engine stop sig disabled" 1 "ISG engine stop sig enabled" ;
VAL_ 880 ISG_MOTORING_STATE 0 "Motoring state OFF" 1 "Motoring state ON" ;
VAL_ 880 ISG_DIRECTION 0 "Forward" 1 "Reverse" ;
VAL_ 880 ISG_OPERATING_STATE 0 "No operation" 1 "Cranking" 2 "Generating and charging" ;
VAL_ 1104 ALIVE_COUNTER_ABS_DATA_1 15 "Signal invalid" ;
VAL_ 1104 ABS_ACTUATION_STATUS 3 "Signal Invalid" 2 "ABS is not actuated" 1 "ABS is actuated" 0 "Reserve" ;
VAL_ 1104 BRAKE_SWITCH_STATUS_ABS 3 "Signal Invalid" 2 "Brake not actuated" 1 "Brake actuated" 0 "Reserve" ;
VAL_ 1104 BRAKE_PAD_PRESSURE_FRONT 255 "Signal invalid" ;
VAL_ 1104 EMERGENCY_STOP_SIGNAL_ST 0 "ESS OFF" 1 "ESS ON Lvl 1" 2 "ESS ON Lvl 2" 3 "Signal invalid" ;
VAL_ 1104 DISTANCE_FRONT 4095 "Signal invalid" ;
VAL_ 1104 DISTANCE_REAR 4095 "Signal invalid" ;
VAL_ 1104 ABS_ON_OFF_SET_FDBK 0 "Turn OFF ABS" 1 "Turn ON ABS" ;
VAL_ 1104 ABS_OFF_FEATURE_AVAIL_STATUS 0 "Feature not available" 1 "Enable Turn OFF ABS" 2 "Enable Turn OFF Rear ABS only" 3 "Reserved" ;
VAL_ 1104 BRAKE_PAD_PRESSURE_REAR 255 "Signal invalid" ;
VAL_ 1105 ALIVE_COUNTER_SPEED 15 "Signal invalid" ;
VAL_ 1105 WHEEL_SPEED_REAR 8191 "Signal invalid" ;
VAL_ 1105 WHEEL_SPEED_FRONT 8191 "Signal invalid" ;
VAL_ 1105 WHEEL_SPEED_REAR_STATUS 0 "Reserved" 1 "Sensor in order" 2 "Sensor defect" 3 "Signal invalid" ;
VAL_ 1105 WHEEL_SPEED_FRONT_STATUS 0 "Reserved" 1 "Sensor in order" 2 "Sensor defect" 3 "Signal invalid" ;
VAL_ 1105 LC_STATUS 0 "LC not active" 1 "LC active" 2 "LC error" 3 "LC not available" 4 "LC disabled by Rider" 5 "Reserved" 6 "Reserved" 7 "Signal invalid" ;
VAL_ 1105 NUMBER_OF_LAUNCHES 0 "No launch" 1 "Launch 1" 2 "Launch 2" 3 "Launch 3" ;
VAL_ 1105 ABS_STATUS 0 "ABS- System shut down by driver" 1 "ABS-Control active" 2 "ABS Malfunction" 3 "ABS- System in the release mode" 4 "ABS-System operational" 5 "RLP malfunction" 6 "Cornering ABS not working" 7 "Signal invalid" ;
VAL_ 1109 ALIVE_COUNTER_ABS_FEATURE_EN 15 "Signal Invalid" ;
VAL_ 1109 FEATURE_EN_RLP 0 "Disabled" 1 "Enabled" ;
VAL_ 1109 FEATURE_EN_SDC 0 "Disabled" 1 "Enabled" ;
VAL_ 1109 FEATURE_EN_MLC 0 "Disabled" 1 "Enabled" ;
VAL_ 1109 FEATURE_EN_WC 0 "Disabled" 1 "Enabled" ;
VAL_ 1109 FEATURE_EN_IMU 0 "Disabled" 1 "Enabled" ;
VAL_ 1109 FEATURE_EN_DTC 0 "Disabled" 1 "Enabled" ;
VAL_ 1360 TIMER_SECONDS 16777215 "Signal invalid" ;
VAL_ 1360 ODO_CLUSTER 1048575 "Signal invalid" ;
VAL_ 1360 CLUSTER_VARIANT_CODE 255 "SIGNAL INVALID" 0 "QS=0,CC=0,TC=0,DTC=0" 1 "QS=0,CC=0,TC=1,DTC=0" 2 "QS=0,CC=1,TC=0,DTC=0" 3 "QS=0,CC=1,TC=1,DTC=0" 4 "QS=1,CC=0,TC=0,DTC=0" 5 "QS=1,CC=0,TC=1,DTC=0" 6 "QS=1,CC=1,TC=0,DTC=0" 7 "QS=1,CC=1,TC=1,DTC=0" 8 "QS=0,CC=0,TC=0,DTC=1" 9 "QS=0,CC=0,TC=1,DTC=1" 10 "QS=0,CC=1,TC=0,DTC=1" 11 "QS=0,CC=1,TC=1,DTC=1" 12 "QS=1,CC=0,TC=0,DTC=1" 13 "QS=1,CC=0,TC=1,DTC=1" 14 "QS=1,CC=1,TC=0,DTC=1" 15 "QS=1,CC=1,TC=1,DTC=1" ;
VAL_ 1360 ABS_VEH_CODE 7 "N325/H100" 15 "SIGNAL INVALID" 1 "U400" 2 "U490" 3 "N597" 4 "U712" 5 "U713" 6 "N600" ;
VAL_ 1360 HORN_ENABLE_IP 0 "Horn disable o/p" 1 "Horn enable o/p" ;
VAL_ 1360 HEATED_GRIP_LEVEL_IP 0 "HEAT LEVEL 0" 1 "HEAT LEVEL 1" 2 "HEAT LEVEL 2" 3 "HEAT LEVEL 3" 4 "Reserved" 5 "Reserved" 6 "Reserved" 7 "Level error" ;
VAL_ 1360 PRECONDITION_STAT_SPEEDO 0 "Pre-conditioning inactive" 1 "Pre-conditioning active" ;
VAL_ 1361 FUEL_LEVEL 255 "Signal invalid" ;
VAL_ 1361 PHOTOSENSOR_OUTPUT 255 "Signal invalid" ;
VAL_ 1361 TYRE_PRESSURE_FR 63 "Signal Invalid" ;
VAL_ 1361 TYRE_PRESSURE_RR 63 "Signal Invalid" ;
VAL_ 1361 TPMS_FR_BATTERY 7 "Signal invalid" ;
VAL_ 1361 TPMS_RR_BATTERY 7 "Signal invalid" ;
VAL_ 1361 VEHICLE_BATTERY_VOLTAGE 255 "Signal invalid" ;
VAL_ 1184 TC_ACTIVATION_REASON 0 "TC Not active" 1 "TC Activated for Wheelie control" 2 "TC Activated for Slip control" 3 "Reserved" ;
VAL_ 1184 CORNERING_ABS_STATUS 0 "Cornering ABS not active" 1 "Cornering ABS active" 2 "Reserved" 3 "Reserved" ;
VAL_ 1184 ABS_ACTUATION_DEBUG 0 "ABS Actuated for RLP" 1 "ABS Actuated for Slip control" 2 "ABS is not actuated" 3 "Reserved" ;
VAL_ 1184 WHEEL_SLIP_PERCENTAGE 255 "Signal Invalid" ;
VAL_ 1184 VEHICLE_ACC 255 "Signal Invalid" ;
